VERSION ""

NS_ :

BS_:

BU_: CGW ADU Vector_XXX

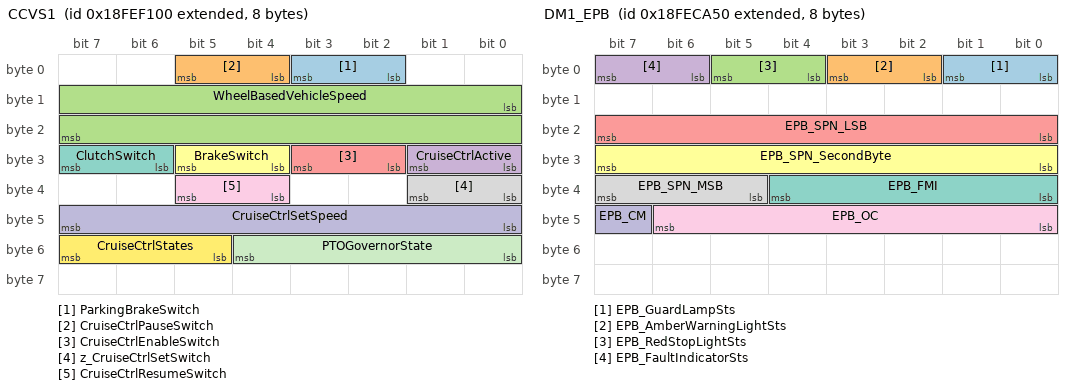
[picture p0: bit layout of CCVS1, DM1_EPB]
BO_ 2566844672 CCVS1: 8 CGW
 SG_ ParkingBrakeSwitch : 2|2@1+ (1,0) [0|3] ""  ADU
 SG_ CruiseCtrlPauseSwitch : 4|2@1+ (1,0) [0|3] ""  ADU
 SG_ WheelBasedVehicleSpeed : 8|16@1+ (0.00390625,0) [0|250.996] "km/h"  ADU
 SG_ CruiseCtrlActive : 24|2@1+ (1,0) [0|3] ""  ADU
 SG_ CruiseCtrlEnableSwitch : 26|2@1+ (1,0) [0|3] ""  ADU
 SG_ BrakeSwitch : 28|2@1+ (1,0) [0|3] ""  ADU
 SG_ ClutchSwitch : 30|2@1+ (1,0) [0|3] ""  ADU
 SG_ z_CruiseCtrlSetSwitch : 32|2@1+ (1,0) [0|3] ""  ADU
 SG_ CruiseCtrlResumeSwitch : 36|2@1+ (1,0) [0|3] ""  ADU
 SG_ CruiseCtrlSetSpeed : 40|8@1+ (1,0) [0|250] "km/h"  ADU
 SG_ PTOGovernorState : 48|5@1+ (1,0) [0|31] ""  ADU
 SG_ CruiseCtrlStates : 53|3@1+ (1,0) [0|7] ""  ADU

BO_ 2565866755 ETC2: 8 CGW
 SG_ SelectedGear : 0|8@1+ (1,-125) [-125|125] ""  ADU
 SG_ ActualGearRatio : 8|16@1+ (0.001,0) [0|64255] ""  ADU
 SG_ CurrentGear : 24|8@1+ (1,-125) [-125|125] ""  ADU

BO_ 2566834768 DM1_EPB: 8 CGW
 SG_ EPB_GuardLampSts : 0|2@1+ (1,0) [0|3] ""  ADU
 SG_ EPB_AmberWarningLightSts : 2|2@1+ (1,0) [0|3] ""  ADU
 SG_ EPB_RedStopLightSts : 4|2@1+ (1,0) [0|3] ""  ADU
 SG_ EPB_FaultIndicatorSts : 6|2@1+ (1,0) [0|3] ""  ADU
 SG_ EPB_SPN_LSB : 16|8@1+ (1,0) [0|255] ""  ADU
 SG_ EPB_SPN_SecondByte : 24|8@1+ (1,0) [0|255] ""  ADU
 SG_ EPB_FMI : 32|5@1+ (1,0) [0|31] ""  ADU
 SG_ EPB_SPN_MSB : 37|3@1+ (1,0) [0|7] ""  ADU
 SG_ EPB_OC : 40|7@1+ (1,0) [0|126] ""  ADU
 SG_ EPB_CM : 47|1@1+ (1,0) [0|1] ""  ADU

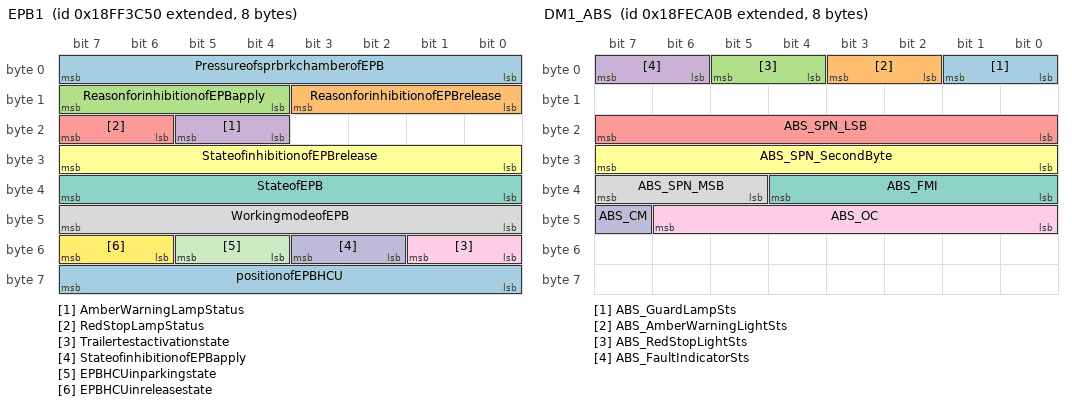
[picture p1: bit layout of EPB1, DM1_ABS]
BO_ 2566863952 EPB1: 8 CGW
 SG_ PressureofsprbrkchamberofEPB : 0|8@1+ (8,0) [0|2000] "kPa"  ADU
 SG_ ReasonforinhibitionofEPBrelease : 8|4@1+ (1,0) [0|15] ""  ADU
 SG_ ReasonforinhibitionofEPBapply : 12|4@1+ (1,0) [0|15] ""  ADU
 SG_ AmberWarningLampStatus : 20|2@1+ (1,0) [0|3] ""  ADU
 SG_ RedStopLampStatus : 22|2@1+ (1,0) [0|3] ""  ADU
 SG_ StateofinhibitionofEPBrelease : 24|8@1+ (1,0) [0|255] ""  ADU
 SG_ StateofEPB : 32|8@1+ (1,0) [0|255] ""  ADU
 SG_ WorkingmodeofEPB : 40|8@1+ (1,0) [0|255] ""  ADU
 SG_ Trailertestactivationstate : 48|2@1+ (1,0) [0|3] ""  ADU
 SG_ StateofinhibitionofEPBapply : 50|2@1+ (1,0) [0|3] ""  ADU
 SG_ EPBHCUinparkingstate : 52|2@1+ (1,0) [0|3] ""  ADU
 SG_ EPBHCUinreleasestate : 54|2@1+ (1,0) [0|3] ""  ADU
 SG_ positionofEPBHCU : 56|8@1+ (1,-125) [-125|125] "%"  ADU

BO_ 2566834699 DM1_ABS: 8 CGW
 SG_ ABS_GuardLampSts : 0|2@1+ (1,0) [0|3] ""  ADU
 SG_ ABS_AmberWarningLightSts : 2|2@1+ (1,0) [0|3] ""  ADU
 SG_ ABS_RedStopLightSts : 4|2@1+ (1,0) [0|3] ""  ADU
 SG_ ABS_FaultIndicatorSts : 6|2@1+ (1,0) [0|3] ""  ADU
 SG_ ABS_SPN_LSB : 16|8@1+ (1,0) [0|255] ""  ADU
 SG_ ABS_SPN_SecondByte : 24|8@1+ (1,0) [0|255] ""  ADU
 SG_ ABS_FMI : 32|5@1+ (1,0) [0|31] ""  ADU
 SG_ ABS_SPN_MSB : 37|3@1+ (1,0) [0|7] ""  ADU
 SG_ ABS_OC : 40|7@1+ (1,0) [0|126] ""  ADU
 SG_ ABS_CM : 47|1@1+ (1,0) [0|1] ""  ADU

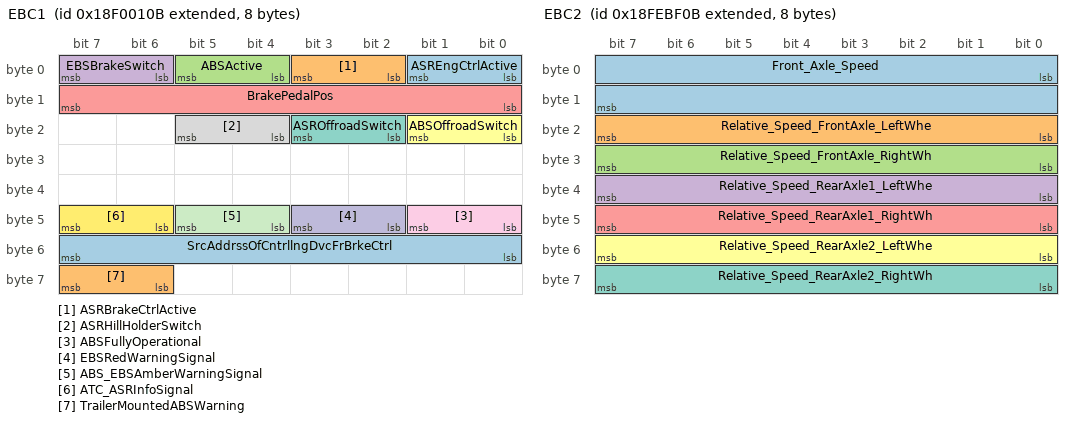
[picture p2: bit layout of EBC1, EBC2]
BO_ 2565865739 EBC1: 8 CGW
 SG_ ASREngCtrlActive : 0|2@1+ (1,0) [0|3] ""  ADU
 SG_ ASRBrakeCtrlActive : 2|2@1+ (1,0) [0|3] ""  ADU
 SG_ ABSActive : 4|2@1+ (1,0) [0|3] ""  ADU
 SG_ EBSBrakeSwitch : 6|2@1+ (1,0) [0|3] ""  ADU
 SG_ BrakePedalPos : 8|8@1+ (0.4,0) [0|100] "%"  ADU
 SG_ ABSOffroadSwitch : 16|2@1+ (1,0) [0|3] ""  ADU
 SG_ ASROffroadSwitch : 18|2@1+ (1,0) [0|3] ""  ADU
 SG_ ASRHillHolderSwitch : 20|2@1+ (1,0) [0|3] ""  ADU
 SG_ ABSFullyOperational : 40|2@1+ (1,0) [0|3] ""  ADU
 SG_ EBSRedWarningSignal : 42|2@1+ (1,0) [0|3] ""  ADU
 SG_ ABS_EBSAmberWarningSignal : 44|2@1+ (1,0) [0|3] ""  ADU
 SG_ ATC_ASRInfoSignal : 46|2@1+ (1,0) [0|3] ""  ADU
 SG_ SrcAddrssOfCntrllngDvcFrBrkeCtrl : 48|8@1+ (1,0) [0|253] ""  ADU
 SG_ TrailerMountedABSWarning : 62|2@1+ (1,0) [0|3] ""  ADU

BO_ 2566831883 EBC2: 8 CGW
 SG_ Front_Axle_Speed : 0|16@1+ (0.00390625,0) [0|250.996] "km/h"  ADU
 SG_ Relative_Speed_FrontAxle_LeftWhe : 16|8@1+ (0.0625,-7.8125) [-7.8125|7.8125] "km/h"  ADU
 SG_ Relative_Speed_FrontAxle_RightWh : 24|8@1+ (0.0625,-7.8125) [-7.8125|7.8125] "km/h"  ADU
 SG_ Relative_Speed_RearAxle1_LeftWhe : 32|8@1+ (0.0625,-7.8125) [-7.8125|7.8125] "km/h"  ADU
 SG_ Relative_Speed_RearAxle1_RightWh : 40|8@1+ (0.0625,-7.8125) [-7.8125|7.8125] "km/h"  ADU
 SG_ Relative_Speed_RearAxle2_LeftWhe : 48|8@1+ (0.0625,-7.8125) [-7.8125|7.8125] "km/h"  ADU
 SG_ Relative_Speed_RearAxle2_RightWh : 56|8@1+ (0.0625,-7.8125) [-7.8125|7.8125] "km/h"  ADU

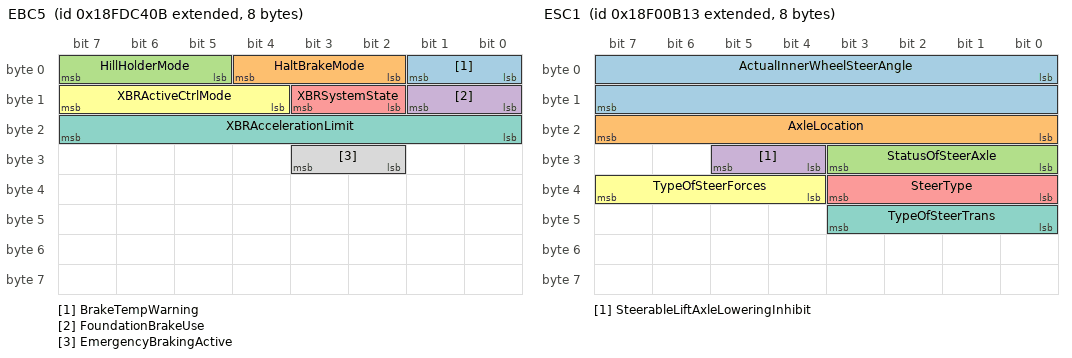
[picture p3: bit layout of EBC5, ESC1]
BO_ 2566767627 EBC5: 8 CGW
 SG_ BrakeTempWarning : 0|2@1+ (1,0) [0|3] ""  ADU
 SG_ HaltBrakeMode : 2|3@1+ (1,0) [0|7] ""  ADU
 SG_ HillHolderMode : 5|3@1+ (1,0) [0|7] ""  ADU
 SG_ FoundationBrakeUse : 8|2@1+ (1,0) [0|3] ""  ADU
 SG_ XBRSystemState : 10|2@1+ (1,0) [0|3] ""  ADU
 SG_ XBRActiveCtrlMode : 12|4@1+ (1,0) [0|15] ""  ADU
 SG_ XBRAccelerationLimit : 16|8@1+ (0.1,-12.5) [-12.5|12.5] "m/s2"  ADU
 SG_ EmergencyBrakingActive : 26|2@1+ (1,0) [0|3] ""  ADU

BO_ 2565868307 ESC1: 8 CGW
 SG_ ActualInnerWheelSteerAngle : 0|16@1+ (0.00390625,-125) [-125|125] "deg"  ADU
 SG_ AxleLocation : 16|8@1+ (1,0) [0|255] ""  ADU
 SG_ StatusOfSteerAxle : 24|4@1+ (1,0) [0|15] ""  ADU
 SG_ SteerableLiftAxleLoweringInhibit : 28|2@1+ (1,0) [0|3] ""  ADU
 SG_ SteerType : 32|4@1+ (1,0) [0|15] ""  ADU
 SG_ TypeOfSteerForces : 36|4@1+ (1,0) [0|15] ""  ADU
 SG_ TypeOfSteerTrans : 40|4@1+ (1,0) [0|15] ""  ADU

BO_ 2566811659 CVW: 8 CGW
 SG_ PoweredVehicleWeight : 0|16@1+ (10,0) [0|642550] "kg"  ADU
 SG_ GrossCombinationVehicleWeight : 16|16@1+ (10,0) [0|642550] "kg"  ADU

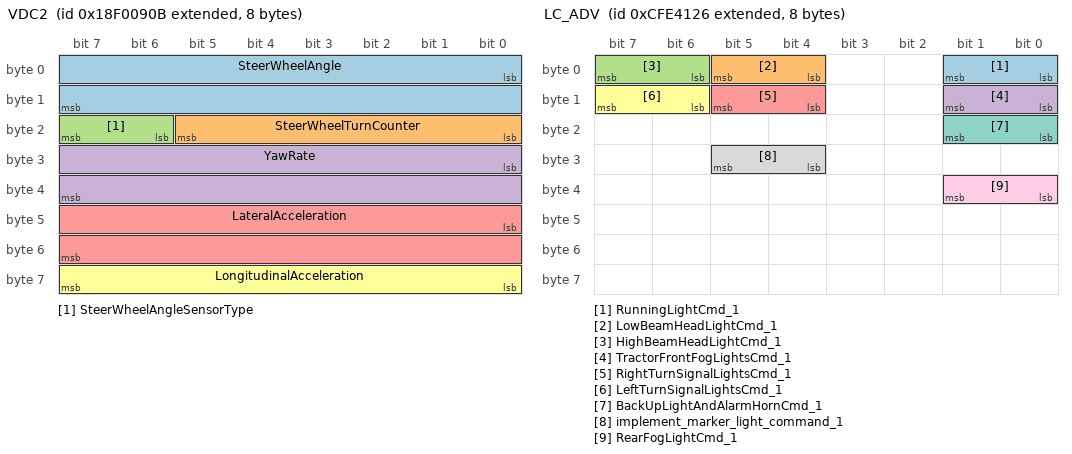
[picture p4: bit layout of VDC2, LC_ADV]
BO_ 2565867787 VDC2: 8 CGW
 SG_ SteerWheelAngle : 0|16@1+ (0.0009765625,-31.375) [-31.375|31.374] "rad"  ADU
 SG_ SteerWheelTurnCounter : 16|6@1+ (1,-32) [-32|31] "turns"  ADU
 SG_ SteerWheelAngleSensorType : 22|2@1+ (1,0) [0|3] ""  ADU
 SG_ YawRate : 24|16@1+ (0.0001220703125,-3.92) [-3.92|3.92] "rad/s"  ADU
 SG_ LateralAcceleration : 40|16@1+ (0.00048828125,-15.687) [-15.687|15.687] "m/s2"  ADU
 SG_ LongitudinalAcceleration : 56|8@1+ (0.1,-12.5) [-12.5|12.5] "m/s2"  ADU

BO_ 2365473062 LC_ADV: 8 ADU
 SG_ RunningLightCmd_1 : 0|2@1+ (1,0) [0|3] ""  CGW
 SG_ LowBeamHeadLightCmd_1 : 4|2@1+ (1,0) [0|3] ""  CGW
 SG_ HighBeamHeadLightCmd_1 : 6|2@1+ (1,0) [0|3] ""  CGW
 SG_ TractorFrontFogLightsCmd_1 : 8|2@1+ (1,0) [0|3] ""  CGW
 SG_ RightTurnSignalLightsCmd_1 : 12|2@1+ (1,0) [0|3] ""  CGW
 SG_ LeftTurnSignalLightsCmd_1 : 14|2@1+ (1,0) [0|3] ""  CGW
 SG_ BackUpLightAndAlarmHornCmd_1 : 16|2@1+ (1,0) [0|3] ""  CGW
 SG_ implement_marker_light_command_1 : 28|2@1+ (1,0) [0|3] ""  CGW
 SG_ RearFogLightCmd_1 : 32|2@1+ (1,0) [0|3] ""  CGW

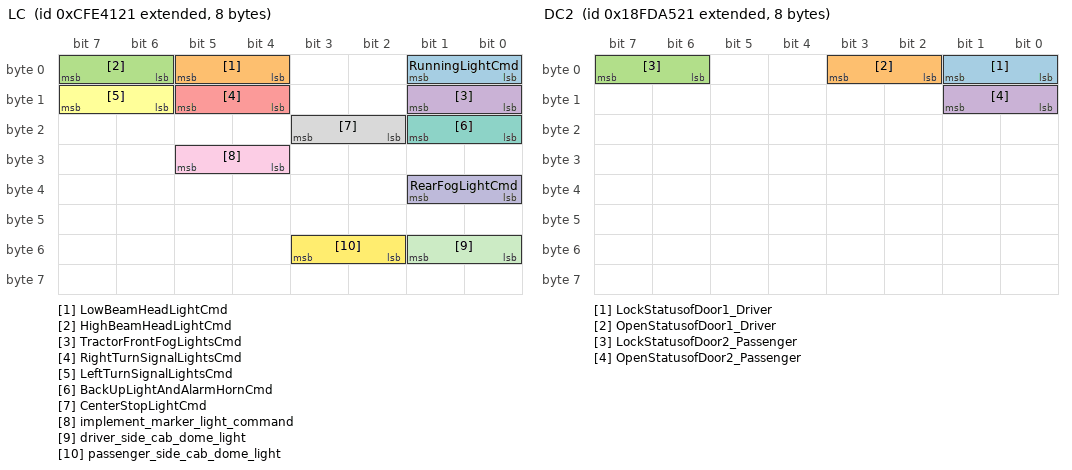
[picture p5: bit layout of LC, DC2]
BO_ 2365473057 LC: 8 CGW
 SG_ RunningLightCmd : 0|2@1+ (1,0) [0|3] ""  ADU
 SG_ LowBeamHeadLightCmd : 4|2@1+ (1,0) [0|3] ""  ADU
 SG_ HighBeamHeadLightCmd : 6|2@1+ (1,0) [0|3] ""  ADU
 SG_ TractorFrontFogLightsCmd : 8|2@1+ (1,0) [0|3] ""  ADU
 SG_ RightTurnSignalLightsCmd : 12|2@1+ (1,0) [0|3] ""  ADU
 SG_ LeftTurnSignalLightsCmd : 14|2@1+ (1,0) [0|3] ""  ADU
 SG_ BackUpLightAndAlarmHornCmd : 16|2@1+ (1,0) [0|3] ""  ADU
 SG_ CenterStopLightCmd : 18|2@1+ (1,0) [0|3] ""  ADU
 SG_ implement_marker_light_command : 28|2@1+ (1,0) [0|3] ""  ADU
 SG_ RearFogLightCmd : 32|2@1+ (1,0) [0|3] ""  ADU
 SG_ driver_side_cab_dome_light : 48|2@1+ (1,0) [0|3] ""  ADU
 SG_ passenger_side_cab_dome_light : 50|2@1+ (1,0) [0|3] ""  ADU

BO_ 2566759713 DC2: 8 CGW
 SG_ LockStatusofDoor1_Driver : 0|2@1+ (1,0) [0|3] ""  ADU
 SG_ OpenStatusofDoor1_Driver : 2|2@1+ (1,0) [0|3] ""  ADU
 SG_ LockStatusofDoor2_Passenger : 6|2@1+ (1,0) [0|3] ""  ADU
 SG_ OpenStatusofDoor2_Passenger : 8|2@1+ (1,0) [0|3] ""  ADU

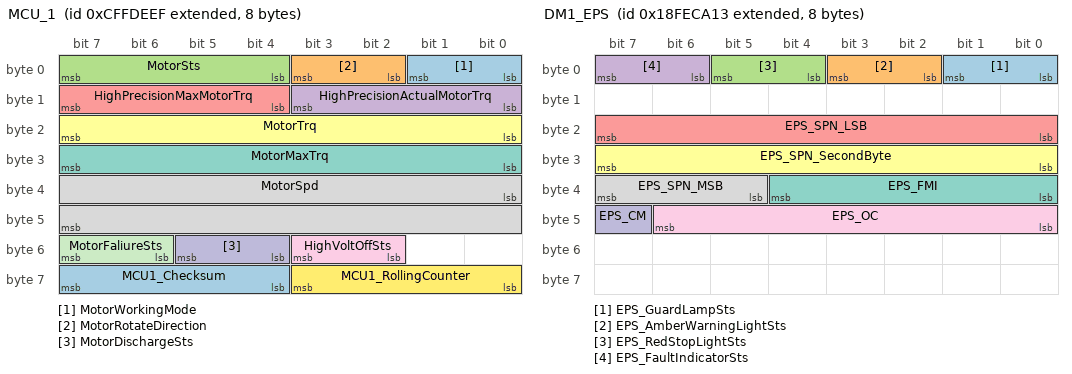
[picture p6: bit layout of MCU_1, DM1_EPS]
BO_ 2365578991 MCU_1: 8 CGW
 SG_ MotorWorkingMode : 0|2@1+ (1,0) [0|3] ""  ADU
 SG_ MotorRotateDirection : 2|2@1+ (1,0) [0|3] ""  ADU
 SG_ MotorSts : 4|4@1+ (1,0) [0|15] ""  ADU
 SG_ HighPrecisionActualMotorTrq : 8|4@1+ (1,0) [0|15] ""  ADU
 SG_ HighPrecisionMaxMotorTrq : 12|4@1+ (1,0) [0|15] ""  ADU
 SG_ MotorTrq : 16|8@1+ (1,-125) [-125|125] "%"  ADU
 SG_ MotorMaxTrq : 24|8@1+ (1,-125) [-125|125] "%"  ADU
 SG_ MotorSpd : 32|16@1+ (0.125,0) [0|8031.875] "rpm"  ADU
 SG_ HighVoltOffSts : 50|2@1+ (1,0) [0|3] ""  ADU
 SG_ MotorDischargeSts : 52|2@1+ (1,0) [0|3] ""  ADU
 SG_ MotorFaliureSts : 54|2@1+ (1,0) [0|3] ""  ADU
 SG_ MCU1_RollingCounter : 56|4@1+ (1,0) [0|15] ""  ADU
 SG_ MCU1_Checksum : 60|4@1+ (1,0) [0|15] ""  ADU

BO_ 2566834707 DM1_EPS: 8 CGW
 SG_ EPS_GuardLampSts : 0|2@1+ (1,0) [0|3] ""  ADU
 SG_ EPS_AmberWarningLightSts : 2|2@1+ (1,0) [0|3] ""  ADU
 SG_ EPS_RedStopLightSts : 4|2@1+ (1,0) [0|3] ""  ADU
 SG_ EPS_FaultIndicatorSts : 6|2@1+ (1,0) [0|3] ""  ADU
 SG_ EPS_SPN_LSB : 16|8@1+ (1,0) [0|255] ""  ADU
 SG_ EPS_SPN_SecondByte : 24|8@1+ (1,0) [0|255] ""  ADU
 SG_ EPS_FMI : 32|5@1+ (1,0) [0|31] ""  ADU
 SG_ EPS_SPN_MSB : 37|3@1+ (1,0) [0|7] ""  ADU
 SG_ EPS_OC : 40|7@1+ (1,0) [0|126] ""  ADU
 SG_ EPS_CM : 47|1@1+ (1,0) [0|1] ""  ADU

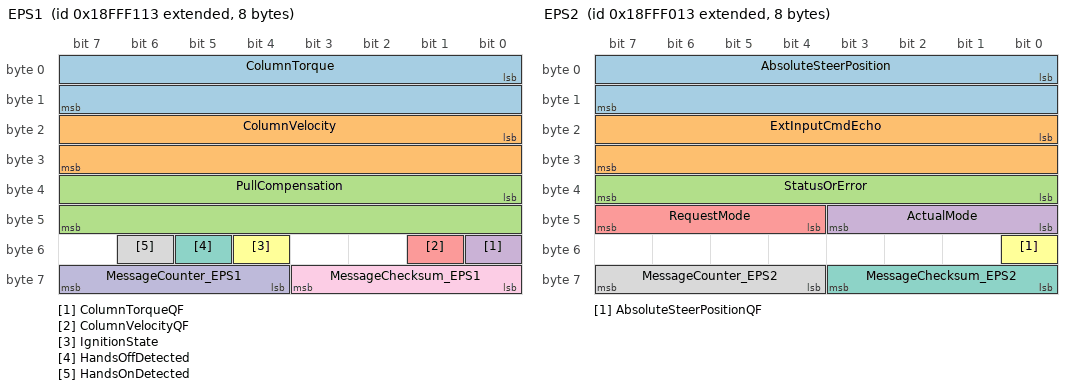
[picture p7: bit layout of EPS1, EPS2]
BO_ 2566910227 EPS1: 8 CGW
 SG_ ColumnTorque : 0|16@1- (0.0009765625,-10) [-10|10] "Nm"  ADU
 SG_ ColumnVelocity : 16|16@1- (0.0009765625,-5) [-5|5] "rev/s"  ADU
 SG_ PullCompensation : 32|16@1- (0.0625,-1024) [-1024|1024] "deg"  ADU
 SG_ ColumnTorqueQF : 48|1@1+ (1,0) [0|1] ""  ADU
 SG_ ColumnVelocityQF : 49|1@1+ (1,0) [0|1] ""  ADU
 SG_ IgnitionState : 52|1@1+ (1,0) [0|1] ""  ADU
 SG_ HandsOffDetected : 53|1@1+ (1,0) [0|1] ""  ADU
 SG_ HandsOnDetected : 54|1@1+ (1,0) [0|1] ""  ADU
 SG_ MessageChecksum_EPS1 : 56|4@1+ (1,0) [0|15] ""  ADU
 SG_ MessageCounter_EPS1 : 60|4@1+ (1,0) [0|15] ""  ADU

BO_ 2566909971 EPS2: 8 CGW
 SG_ AbsoluteSteerPosition : 0|16@1- (0.0625,-1224) [-1224|1224] "deg"  ADU
 SG_ ExtInputCmdEcho : 16|16@1- (0.0625,-1224) [-1224|1224] "deg"  ADU
 SG_ StatusOrError : 32|8@1+ (1,0) [0|0] ""  ADU
 SG_ ActualMode : 40|4@1+ (1,0) [0|15] ""  ADU
 SG_ RequestMode : 44|4@1+ (1,0) [0|15] ""  ADU
 SG_ AbsoluteSteerPositionQF : 48|1@1+ (1,0) [0|1] ""  ADU
 SG_ MessageChecksum_EPS2 : 56|4@1+ (1,0) [0|15] ""  ADU
 SG_ MessageCounter_EPS2 : 60|4@1+ (1,0) [0|15] ""  ADU

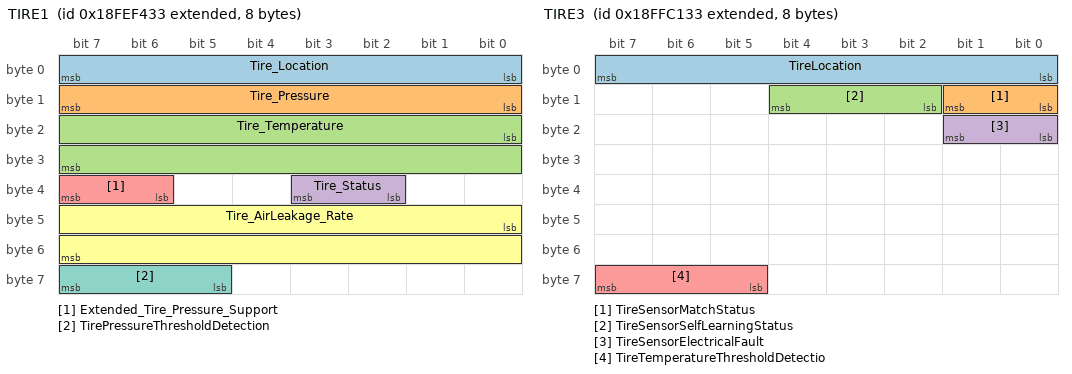
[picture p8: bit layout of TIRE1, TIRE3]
BO_ 2566845491 TIRE1: 8 CGW
 SG_ Tire_Location : 0|8@1+ (1,0) [0|255] ""  ADU
 SG_ Tire_Pressure : 8|8@1+ (4,0) [0|250] "kpa"  ADU
 SG_ Tire_Temperature : 16|16@1+ (0.03125,-273) [-273|1734.96875] "℃"  ADU
 SG_ Tire_Status : 34|2@1+ (1,0) [0|3] ""  ADU
 SG_ Extended_Tire_Pressure_Support : 38|2@1+ (1,0) [0|3] ""  ADU
 SG_ Tire_AirLeakage_Rate : 40|16@1+ (0.1,0) [0|6425.5] "Pa/s"  ADU
 SG_ TirePressureThresholdDetection : 61|3@1+ (1,0) [0|7] ""  ADU

BO_ 2566668851 TIRE2: 8 CGW
 SG_ Tire_Location : 0|8@1+ (1,0) [0|255] ""  ADU
 SG_ Tire_PressExtedRage : 8|16@1+ (1,0) [0|64255] "kpa"  ADU
 SG_ RequiredTirePressure : 24|16@1+ (1,0) [0|64255] "kpa"  ADU

BO_ 2566897971 TIRE3: 8 CGW
 SG_ TireLocation : 0|8@1+ (1,0) [0|255] ""  ADU
 SG_ TireSensorMatchStatus : 8|2@1+ (1,0) [0|3] ""  ADU
 SG_ TireSensorSelfLearningStatus : 10|3@1+ (1,0) [0|7] ""  ADU
 SG_ TireSensorElectricalFault : 16|2@1+ (1,0) [0|3] ""  ADU
 SG_ TireTemperatureThresholdDetectio : 61|3@1+ (1,0) [0|7] ""  ADU

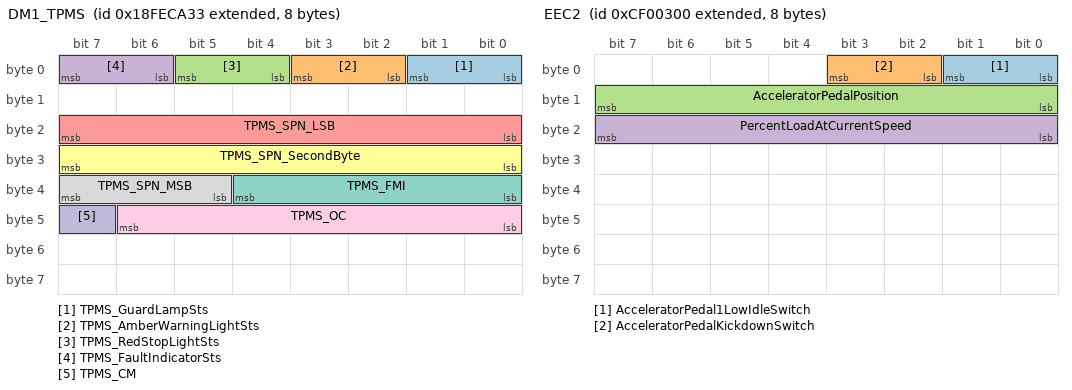
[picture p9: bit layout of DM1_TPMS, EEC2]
BO_ 2566834739 DM1_TPMS: 8 CGW
 SG_ TPMS_GuardLampSts : 0|2@1+ (1,0) [0|3] ""  ADU
 SG_ TPMS_AmberWarningLightSts : 2|2@1+ (1,0) [0|3] ""  ADU
 SG_ TPMS_RedStopLightSts : 4|2@1+ (1,0) [0|3] ""  ADU
 SG_ TPMS_FaultIndicatorSts : 6|2@1+ (1,0) [0|3] ""  ADU
 SG_ TPMS_SPN_LSB : 16|8@1+ (1,0) [0|255] ""  ADU
 SG_ TPMS_SPN_SecondByte : 24|8@1+ (1,0) [0|255] ""  ADU
 SG_ TPMS_FMI : 32|5@1+ (1,0) [0|31] ""  ADU
 SG_ TPMS_SPN_MSB : 37|3@1+ (1,0) [0|7] ""  ADU
 SG_ TPMS_OC : 40|7@1+ (1,0) [0|126] ""  ADU
 SG_ TPMS_CM : 47|1@1+ (1,0) [0|1] ""  ADU

BO_ 2364539648 EEC2: 8 CGW
 SG_ AcceleratorPedal1LowIdleSwitch : 0|2@1+ (1,0) [0|3] ""  ADU
 SG_ AcceleratorPedalKickdownSwitch : 2|2@1+ (1,0) [0|3] ""  ADU
 SG_ AcceleratorPedalPosition : 8|8@1+ (0.4,0) [0|100] "%"  ADU
 SG_ PercentLoadAtCurrentSpeed : 16|8@1+ (1,0) [0|250] "%"  ADU

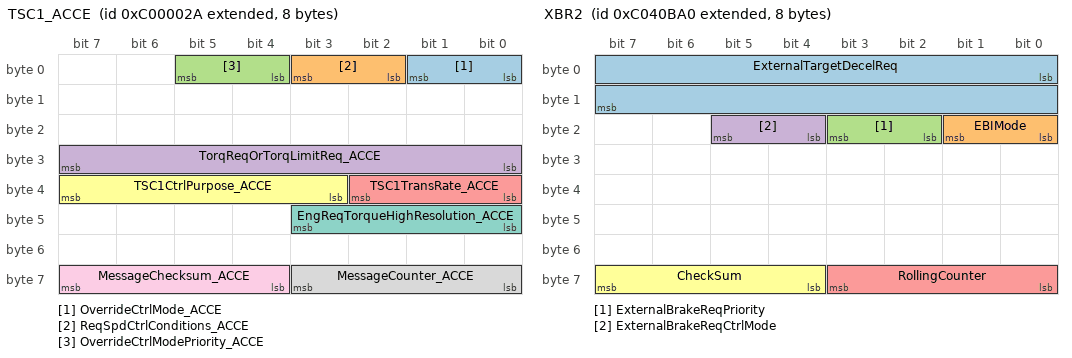
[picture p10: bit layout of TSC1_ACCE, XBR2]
BO_ 2348810282 TSC1_ACCE: 8 ADU
 SG_ OverrideCtrlMode_ACCE : 0|2@1+ (1,0) [0|3] ""  CGW
 SG_ ReqSpdCtrlConditions_ACCE : 2|2@1+ (1,0) [0|3] ""  CGW
 SG_ OverrideCtrlModePriority_ACCE : 4|2@1+ (1,0) [0|3] ""  CGW
 SG_ TorqReqOrTorqLimitReq_ACCE : 24|8@1+ (1,-125) [-125|125] "%"  CGW
 SG_ TSC1TransRate_ACCE : 32|3@1+ (1,0) [0|7] ""  CGW
 SG_ TSC1CtrlPurpose_ACCE : 35|5@1+ (1,0) [0|31] ""  CGW
 SG_ EngReqTorqueHighResolution_ACCE : 40|4@1+ (0.125,0) [0|0.875] "%"  CGW
 SG_ MessageCounter_ACCE : 56|4@1+ (1,0) [0|15] ""  CGW
 SG_ MessageChecksum_ACCE : 60|4@1+ (1,0) [0|15] ""  CGW

BO_ 2349075360 XBR2: 8 ADU
 SG_ ExternalTargetDecelReq : 0|16@1+ (0.0004882813,-15.687) [-15.687|15.687] "m/s2"  CGW
 SG_ EBIMode : 16|2@1+ (1,0) [0|3] ""  CGW
 SG_ ExternalBrakeReqPriority : 18|2@1+ (1,0) [0|3] ""  CGW
 SG_ ExternalBrakeReqCtrlMode : 20|2@1+ (1,0) [0|3] ""  CGW
 SG_ RollingCounter : 56|4@1+ (1,0) [0|15] ""  CGW
 SG_ CheckSum : 60|4@1+ (1,0) [0|15] ""  CGW

BO_ 2348875814 TC1_ADU: 8 ADU
 SG_ TransmissionGearReq : 16|8@1+ (1,-125) [-125|125] ""  CGW

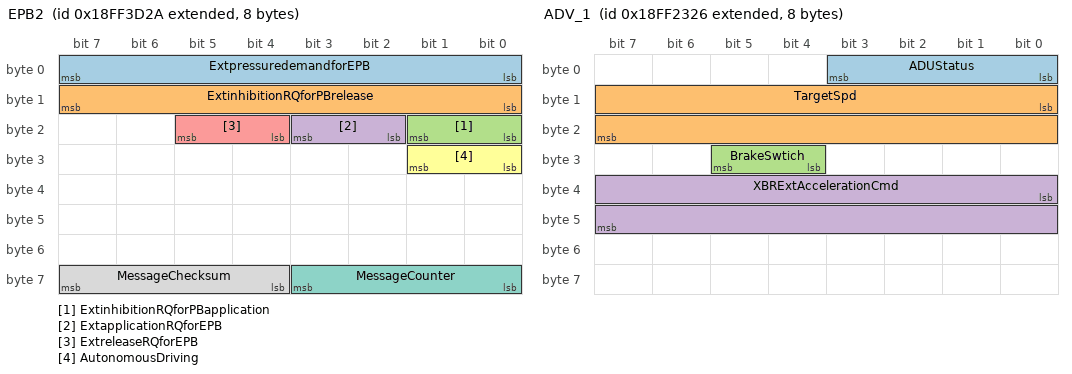
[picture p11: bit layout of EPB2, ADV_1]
BO_ 2566864170 EPB2: 8 ADU
 SG_ ExtpressuredemandforEPB : 0|8@1+ (0.4,0) [0|100] "%"  CGW
 SG_ ExtinhibitionRQforPBrelease : 8|8@1+ (1,0) [0|255] ""  CGW
 SG_ ExtinhibitionRQforPBapplication : 16|2@1+ (1,0) [0|3] ""  CGW
 SG_ ExtapplicationRQforEPB : 18|2@1+ (1,0) [0|3] ""  CGW
 SG_ ExtreleaseRQforEPB : 20|2@1+ (1,0) [0|3] ""  CGW
 SG_ AutonomousDriving : 24|2@1+ (1,0) [0|3] ""  CGW
 SG_ MessageCounter : 56|4@1+ (1,0) [0|15] ""  CGW
 SG_ MessageChecksum : 60|4@1+ (1,0) [0|15] ""  CGW

BO_ 2566857510 ADV_1: 8 ADU
 SG_ ADUStatus : 0|4@1+ (1,0) [0|15] ""  CGW
 SG_ TargetSpd : 8|16@1+ (0.00390625,0) [0|250.996] "km/h"  CGW
 SG_ BrakeSwtich : 28|2@1+ (1,0) [0|3] ""  CGW
 SG_ XBRExtAccelerationCmd : 32|16@1+ (0.00048828,-15.687) [-15.687|15.687] "m/s2"  CGW

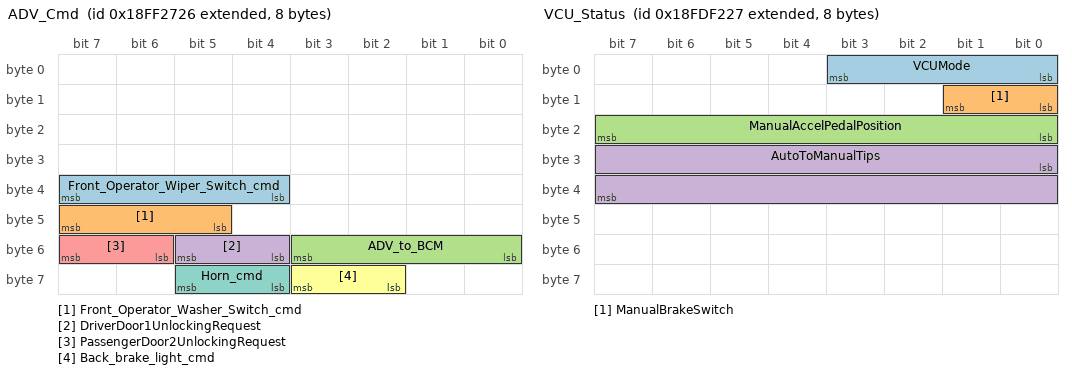
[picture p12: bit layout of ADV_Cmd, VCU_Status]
BO_ 2566858534 ADV_Cmd: 8 ADU
 SG_ Front_Operator_Wiper_Switch_cmd : 36|4@1+ (1,0) [0|8] ""  CGW
 SG_ Front_Operator_Washer_Switch_cmd : 45|3@1+ (1,0) [0|7] ""  CGW
 SG_ ADV_to_BCM : 48|4@1+ (1,0) [0|15] ""  CGW
 SG_ DriverDoor1UnlockingRequest : 52|2@1+ (1,0) [0|3] ""  Vector_XXX
 SG_ PassengerDoor2UnlockingRequest : 54|2@1+ (1,0) [0|3] ""  Vector_XXX
 SG_ Back_brake_light_cmd : 58|2@1+ (1,0) [0|3] ""  CGW
 SG_ Horn_cmd : 60|2@1+ (1,0) [0|3] ""  CGW

BO_ 2566779431 VCU_Status: 8 CGW
 SG_ VCUMode : 0|4@1+ (1,0) [0|15] ""  ADU
 SG_ ManualBrakeSwitch : 8|2@1+ (1,0) [0|3] ""  ADU
 SG_ ManualAccelPedalPosition : 16|8@1+ (0.4,0) [0|100] "%"  ADU
 SG_ AutoToManualTips : 24|16@1+ (1,0) [0|65535] ""  ADU

BO_ 2566769953 OWW: 8 CGW
 SG_ FrontOperatorWiperSwitch : 4|4@1+ (1,0) [0|15] ""  ADU
 SG_ FrontOperatorWasherSwitch : 45|3@1+ (1,0) [0|7] ""  ADU

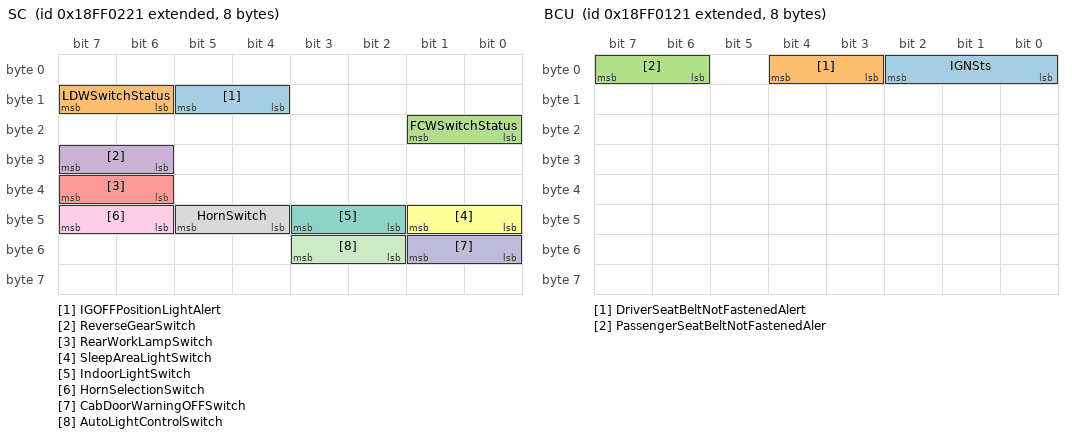
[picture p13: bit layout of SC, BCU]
BO_ 2566849057 SC: 8 CGW
 SG_ IGOFFPositionLightAlert : 12|2@1+ (1,0) [0|3] ""  ADU
 SG_ LDWSwitchStatus : 14|2@1+ (1,0) [0|3] ""  ADU
 SG_ FCWSwitchStatus : 16|2@1+ (1,0) [0|3] ""  ADU
 SG_ ReverseGearSwitch : 30|2@1+ (1,0) [0|3] ""  ADU
 SG_ RearWorkLampSwitch : 38|2@1+ (1,0) [0|3] ""  ADU
 SG_ SleepAreaLightSwitch : 40|2@1+ (1,0) [0|3] ""  ADU
 SG_ IndoorLightSwitch : 42|2@1+ (1,0) [0|3] ""  ADU
 SG_ HornSwitch : 44|2@1+ (1,0) [0|3] ""  ADU
 SG_ HornSelectionSwitch : 46|2@1+ (1,0) [0|3] ""  ADU
 SG_ CabDoorWarningOFFSwitch : 48|2@1+ (1,0) [0|3] ""  ADU
 SG_ AutoLightControlSwitch : 50|2@1+ (1,0) [0|3] ""  ADU

BO_ 2566848801 BCU: 8 CGW
 SG_ IGNSts : 0|3@1+ (1,0) [0|7] ""  ADU
 SG_ DriverSeatBeltNotFastenedAlert : 3|2@1+ (1,0) [0|3] ""  ADU
 SG_ PassengerSeatBeltNotFastenedAler : 6|2@1+ (1,0) [0|3] ""  ADU

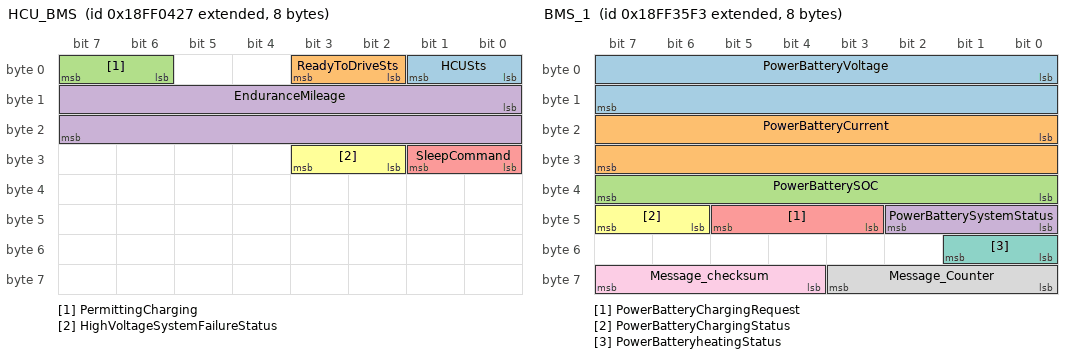
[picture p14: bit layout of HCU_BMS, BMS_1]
BO_ 2566849575 HCU_BMS: 8 CGW
 SG_ HCUSts : 0|2@1+ (1,0) [0|3] ""  ADU
 SG_ ReadyToDriveSts : 2|2@1+ (1,0) [0|3] ""  ADU
 SG_ PermittingCharging : 6|2@1+ (1,0) [0|3] ""  ADU
 SG_ EnduranceMileage : 8|16@1+ (0.125,0) [0|8031.875] "km"  ADU
 SG_ SleepCommand : 24|2@1+ (1,0) [0|3] ""  ADU
 SG_ HighVoltageSystemFailureStatus : 26|2@1+ (1,0) [0|3] ""  ADU

BO_ 2566862323 BMS_1: 8 CGW
 SG_ PowerBatteryVoltage : 0|16@1+ (0.05,0) [0|3212.75] "V"  ADU
 SG_ PowerBatteryCurrent : 16|16@1+ (0.05,-1600) [-1600|1612.75] "A"  ADU
 SG_ PowerBatterySOC : 32|8@1+ (1,0) [0|100] ""  ADU
 SG_ PowerBatterySystemStatus : 40|3@1+ (1,0) [0|7] ""  ADU
 SG_ PowerBatteryChargingRequest : 43|3@1+ (1,0) [0|7] ""  ADU
 SG_ PowerBatteryChargingStatus : 46|2@1+ (1,0) [0|3] ""  ADU
 SG_ PowerBatteryheatingStatus : 48|2@1+ (1,0) [0|3] ""  ADU
 SG_ Message_Counter : 56|4@1+ (1,0) [0|15] ""  ADU
 SG_ Message_checksum : 60|4@1+ (1,0) [0|15] ""  ADU

BO_ 2566863603 BMS_5: 8 CGW
 SG_ BMSMainnegativeCoilDriveState : 14|2@1+ (1,0) [0|3] ""  ADU
 SG_ PowerBatterySOH : 16|8@1+ (0.4,0) [0|100] "%"  ADU
 SG_ MainNegativeRelayDisconnectReque : 38|2@1+ (1,0) [0|3] ""  ADU
 SG_ MainNegativeRelayStatus : 40|3@1+ (1,0) [0|7] ""  ADU
 SG_ PositiveRelayControlCommand : 43|2@1+ (1,0) [0|3] ""  ADU
 SG_ NegativeRelayControlCommand : 46|2@1+ (1,0) [0|3] ""  ADU
 SG_ ChargingPlugConnectionStatus : 48|2@1+ (1,0) [0|3] ""  ADU
 SG_ ChargingPlugConnectionStatus2 : 50|2@0+ (1,0) [0|3] ""  Vector_XXX
 SG_ PositiveRelayStatus : 56|3@1+ (1,0) [0|7] ""  ADU
 SG_ NegativeRelayStatus : 59|3@1+ (1,0) [0|7] ""  ADU

BO_ 2566840343 VD: 8 CGW
 SG_ TripDistance : 0|32@1+ (0.125,0) [0|526385151.9] "km"  ADU
 SG_ TotalVehicleDistance : 32|32@1+ (0.125,0) [0|526385151.9] "km"  ADU

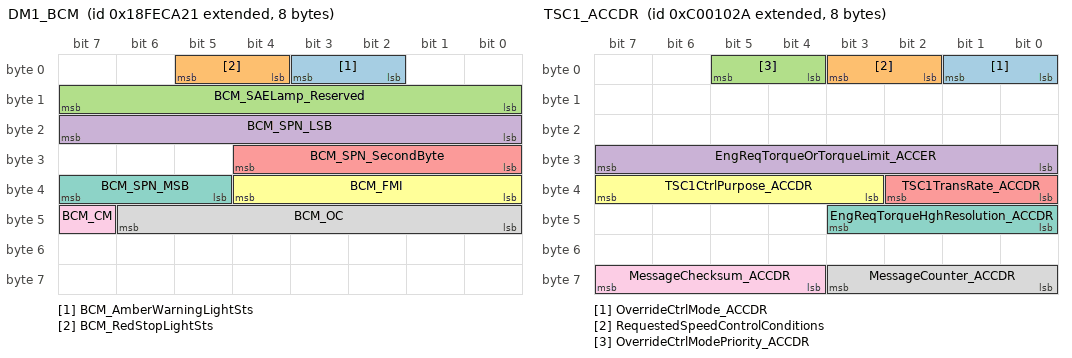
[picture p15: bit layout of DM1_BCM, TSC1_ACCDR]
BO_ 2566834721 DM1_BCM: 8 CGW
 SG_ BCM_AmberWarningLightSts : 2|2@1+ (1,0) [0|3] ""  ADU
 SG_ BCM_RedStopLightSts : 4|2@1+ (1,0) [0|3] ""  ADU
 SG_ BCM_SAELamp_Reserved : 8|8@1+ (1,0) [0|255] ""  ADU
 SG_ BCM_SPN_LSB : 16|8@1+ (1,0) [0|255] ""  ADU
 SG_ BCM_SPN_SecondByte : 24|5@1+ (1,0) [0|31] ""  ADU
 SG_ BCM_FMI : 32|5@1+ (1,0) [0|31] ""  ADU
 SG_ BCM_SPN_MSB : 37|3@1+ (1,0) [0|7] ""  ADU
 SG_ BCM_OC : 40|7@1+ (1,0) [0|126] ""  ADU
 SG_ BCM_CM : 47|1@1+ (1,0) [0|1] ""  ADU

BO_ 2348814378 TSC1_ACCDR: 8 ADU
 SG_ OverrideCtrlMode_ACCDR : 0|2@1+ (1,0) [0|3] ""  CGW
 SG_ RequestedSpeedControlConditions : 2|2@1+ (1,0) [0|3] ""  CGW
 SG_ OverrideCtrlModePriority_ACCDR : 4|2@1+ (1,0) [0|3] ""  CGW
 SG_ EngReqTorqueOrTorqueLimit_ACCER : 24|8@1+ (1,-125) [-125|125] "%"  CGW
 SG_ TSC1TransRate_ACCDR : 32|3@1+ (1,0) [0|7] ""  CGW
 SG_ TSC1CtrlPurpose_ACCDR : 35|5@1+ (1,0) [0|31] ""  CGW
 SG_ EngReqTorqueHghResolution_ACCDR : 40|4@1+ (0.125,0) [0|0.875] ""  CGW
 SG_ MessageCounter_ACCDR : 56|4@1+ (1,0) [0|15] ""  CGW
 SG_ MessageChecksum_ACCDR : 60|4@1+ (1,0) [0|15] ""  CGW

BO_ 2566841127 EC_EM1: 40 CGW
 SG_ EngineSpeedAtIdle_Point1 : 0|16@1+ (0.125,0) [0|8031.875] "km"  ADU
 SG_ Reference_engine_torque_Drive : 152|16@1+ (1,0) [0|64255] "Nm"  ADU
 SG_ SupportVariableRateTSC1 : 272|8@1+ (1,0) [0|255] ""  ADU

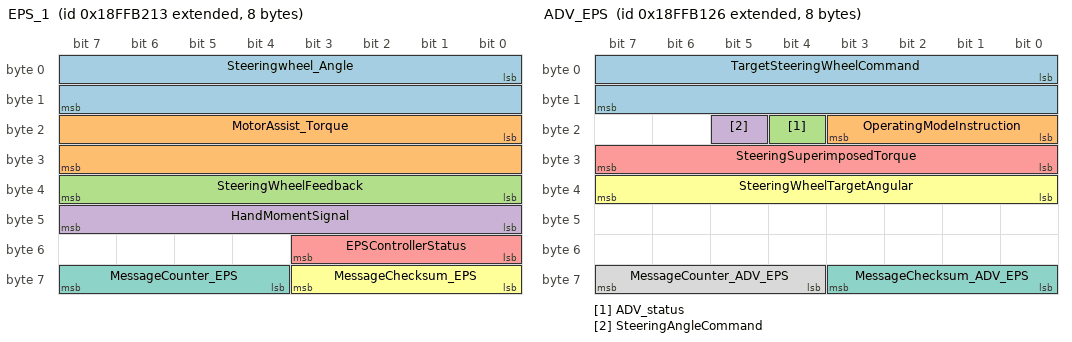
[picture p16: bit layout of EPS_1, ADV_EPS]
BO_ 2566894099 EPS_1: 8 CGW
 SG_ Steeringwheel_Angle : 0|16@1+ (0.1,-1575) [-1575|1575] "°"  ADU
 SG_ MotorAssist_Torque : 16|16@1+ (0.000152,-5) [-5|5] "Nm"  ADU
 SG_ SteeringWheelFeedback : 32|8@1- (10,0) [50|540] "°/s"  ADU
 SG_ HandMomentSignal : 40|8@1+ (0.1,-12.8) [-12.8|12.7] "Nm"  ADU
 SG_ EPSControllerStatus : 48|4@1+ (1,0) [0|15] ""  ADU
 SG_ MessageChecksum_EPS : 56|4@1+ (1,0) [0|15] ""  ADU
 SG_ MessageCounter_EPS : 60|4@1+ (1,0) [0|15] ""  ADU

BO_ 2566893862 ADV_EPS: 8 ADU
 SG_ TargetSteeringWheelCommand : 0|16@1+ (0.1,-1575) [-1575|1575] "°"  ADU
 SG_ OperatingModeInstruction : 16|4@1+ (1,0) [0|15] ""  ADU
 SG_ ADV_status : 20|1@1+ (1,0) [0|1] ""  ADU
 SG_ SteeringAngleCommand : 21|1@1+ (1,0) [0|1] ""  ADU
 SG_ SteeringSuperimposedTorque : 24|8@1+ (1,-12.8) [-12.8|12.7] "Nm"  Vector_XXX
 SG_ SteeringWheelTargetAngular : 32|8@1+ (2,50) [50|540] "°/s"  ADU
 SG_ MessageChecksum_ADV_EPS : 56|4@1+ (1,0) [0|15] ""  ADU
 SG_ MessageCounter_ADV_EPS : 60|4@1+ (1,0) [0|15] ""  ADU

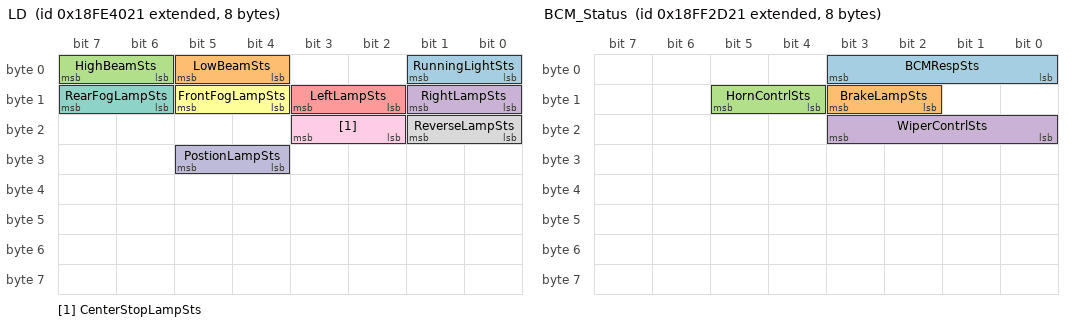
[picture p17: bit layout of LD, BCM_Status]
BO_ 2566799393 LD: 8 CGW
 SG_ RunningLightSts : 0|2@1+ (1,0) [0|3] ""  ADU
 SG_ LowBeamSts : 4|2@1+ (1,0) [0|3] ""  ADU
 SG_ HighBeamSts : 6|2@1+ (1,0) [0|3] ""  ADU
 SG_ RightLampSts : 8|2@1+ (1,0) [0|3] ""  ADU
 SG_ LeftLampSts : 10|2@1+ (1,0) [0|3] ""  ADU
 SG_ FrontFogLampSts : 12|2@1+ (1,0) [0|3] ""  ADU
 SG_ RearFogLampSts : 14|2@1+ (1,0) [0|3] ""  ADU
 SG_ ReverseLampSts : 16|2@1+ (1,0) [0|3] ""  ADU
 SG_ CenterStopLampSts : 18|2@1+ (1,0) [0|3] ""  ADU
 SG_ PostionLampSts : 28|2@1+ (1,0) [0|3] ""  ADU

BO_ 2566860065 BCM_Status: 8 CGW
 SG_ BCMRespSts : 0|4@1+ (1,0) [0|15] ""  ADU
 SG_ BrakeLampSts : 10|2@1+ (1,0) [0|3] ""  ADU
 SG_ HornContrlSts : 12|2@1+ (1,0) [0|3] ""  ADU
 SG_ WiperContrlSts : 16|4@1+ (1,0) [0|3] ""  ADU

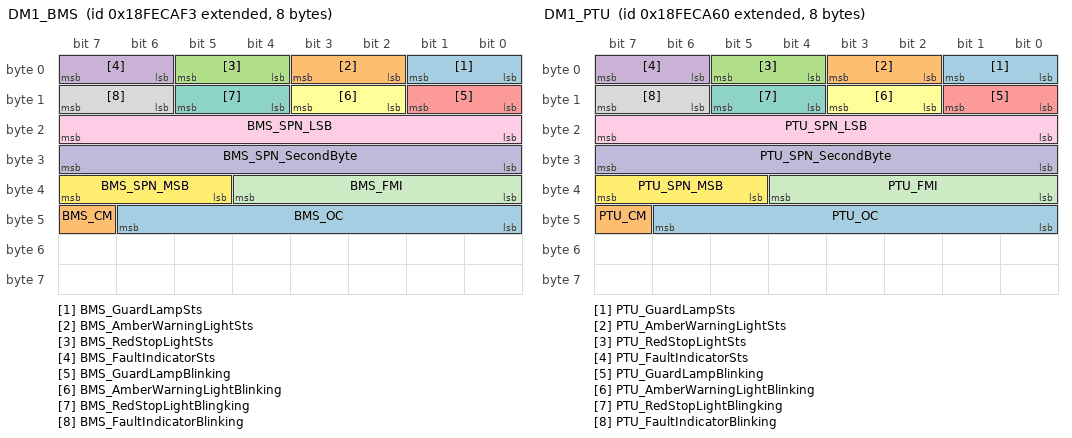
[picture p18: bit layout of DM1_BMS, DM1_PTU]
BO_ 2566834931 DM1_BMS: 8 CGW
 SG_ BMS_GuardLampSts : 0|2@1+ (1,0) [0|3] ""  ADU
 SG_ BMS_AmberWarningLightSts : 2|2@1+ (1,0) [0|3] ""  ADU
 SG_ BMS_RedStopLightSts : 4|2@1+ (1,0) [0|3] ""  ADU
 SG_ BMS_FaultIndicatorSts : 6|2@1+ (1,0) [0|3] ""  ADU
 SG_ BMS_GuardLampBlinking : 8|2@1+ (1,0) [0|3] ""  ADU
 SG_ BMS_AmberWarningLightBlinking : 10|2@1+ (1,0) [0|3] ""  ADU
 SG_ BMS_RedStopLightBlingking : 12|2@1+ (1,0) [0|3] ""  ADU
 SG_ BMS_FaultIndicatorBlinking : 14|2@1+ (1,0) [0|3] ""  ADU
 SG_ BMS_SPN_LSB : 16|8@1+ (1,0) [0|255] ""  ADU
 SG_ BMS_SPN_SecondByte : 31|8@0+ (1,0) [0|255] ""  Vector_XXX
 SG_ BMS_FMI : 32|5@1+ (1,0) [0|31] ""  ADU
 SG_ BMS_SPN_MSB : 37|3@1+ (1,0) [0|7] ""  ADU
 SG_ BMS_OC : 40|7@1+ (1,0) [1|126] ""  ADU
 SG_ BMS_CM : 47|1@1+ (1,0) [0|1] ""  ADU

BO_ 2566834784 DM1_PTU: 8 CGW
 SG_ PTU_GuardLampSts : 0|2@1+ (1,0) [0|3] ""  ADU
 SG_ PTU_AmberWarningLightSts : 2|2@1+ (1,0) [0|3] ""  ADU
 SG_ PTU_RedStopLightSts : 4|2@1+ (1,0) [0|3] ""  ADU
 SG_ PTU_FaultIndicatorSts : 6|2@1+ (1,0) [0|3] ""  ADU
 SG_ PTU_GuardLampBlinking : 8|2@1+ (1,0) [0|3] ""  ADU
 SG_ PTU_AmberWarningLightBlinking : 10|2@1+ (1,0) [0|3] ""  ADU
 SG_ PTU_RedStopLightBlingking : 12|2@1+ (1,0) [0|3] ""  ADU
 SG_ PTU_FaultIndicatorBlinking : 14|2@1+ (1,0) [0|3] ""  ADU
 SG_ PTU_SPN_LSB : 16|8@1+ (1,0) [0|255] ""  ADU
 SG_ PTU_SPN_SecondByte : 31|8@0+ (1,0) [0|255] ""  Vector_XXX
 SG_ PTU_FMI : 32|5@1+ (1,0) [0|31] ""  ADU
 SG_ PTU_SPN_MSB : 37|3@1+ (1,0) [0|7] ""  ADU
 SG_ PTU_OC : 40|7@1+ (1,0) [1|126] ""  ADU
 SG_ PTU_CM : 47|1@1+ (1,0) [0|1] ""  ADU

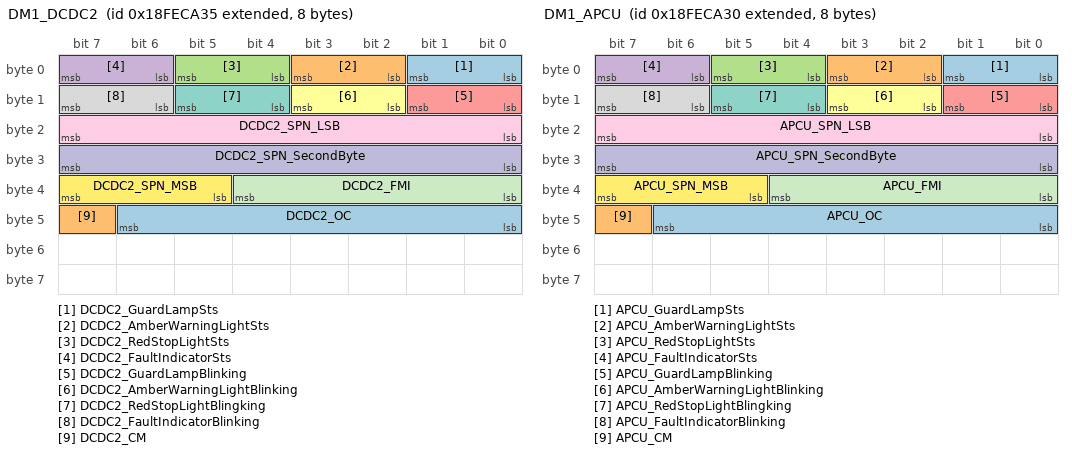
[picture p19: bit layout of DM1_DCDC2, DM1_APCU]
BO_ 2566834741 DM1_DCDC2: 8 CGW
 SG_ DCDC2_GuardLampSts : 0|2@1+ (1,0) [0|3] ""  ADU
 SG_ DCDC2_AmberWarningLightSts : 2|2@1+ (1,0) [0|3] ""  ADU
 SG_ DCDC2_RedStopLightSts : 4|2@1+ (1,0) [0|3] ""  ADU
 SG_ DCDC2_FaultIndicatorSts : 6|2@1+ (1,0) [0|3] ""  ADU
 SG_ DCDC2_GuardLampBlinking : 8|2@1+ (1,0) [0|3] ""  ADU
 SG_ DCDC2_AmberWarningLightBlinking : 10|2@1+ (1,0) [0|3] ""  ADU
 SG_ DCDC2_RedStopLightBlingking : 12|2@1+ (1,0) [0|3] ""  ADU
 SG_ DCDC2_FaultIndicatorBlinking : 14|2@1+ (1,0) [0|3] ""  ADU
 SG_ DCDC2_SPN_LSB : 16|8@1+ (1,0) [0|255] ""  ADU
 SG_ DCDC2_SPN_SecondByte : 31|8@0+ (1,0) [0|255] ""  Vector_XXX
 SG_ DCDC2_FMI : 32|5@1+ (1,0) [0|31] ""  ADU
 SG_ DCDC2_SPN_MSB : 37|3@1+ (1,0) [0|7] ""  ADU
 SG_ DCDC2_OC : 40|7@1+ (1,0) [1|126] ""  ADU
 SG_ DCDC2_CM : 47|1@1+ (1,0) [0|1] ""  ADU

BO_ 2566834736 DM1_APCU: 8 CGW
 SG_ APCU_GuardLampSts : 0|2@1+ (1,0) [0|3] ""  ADU
 SG_ APCU_AmberWarningLightSts : 2|2@1+ (1,0) [0|3] ""  ADU
 SG_ APCU_RedStopLightSts : 4|2@1+ (1,0) [0|3] ""  ADU
 SG_ APCU_FaultIndicatorSts : 6|2@1+ (1,0) [0|3] ""  ADU
 SG_ APCU_GuardLampBlinking : 8|2@1+ (1,0) [0|3] ""  ADU
 SG_ APCU_AmberWarningLightBlinking : 10|2@1+ (1,0) [0|3] ""  ADU
 SG_ APCU_RedStopLightBlingking : 12|2@1+ (1,0) [0|3] ""  ADU
 SG_ APCU_FaultIndicatorBlinking : 14|2@1+ (1,0) [0|3] ""  ADU
 SG_ APCU_SPN_LSB : 16|8@1+ (1,0) [0|255] ""  ADU
 SG_ APCU_SPN_SecondByte : 31|8@0+ (1,0) [0|255] ""  Vector_XXX
 SG_ APCU_FMI : 32|5@1+ (1,0) [0|31] ""  ADU
 SG_ APCU_SPN_MSB : 37|3@1+ (1,0) [0|7] ""  ADU
 SG_ APCU_OC : 40|7@1+ (1,0) [1|126] ""  ADU
 SG_ APCU_CM : 47|1@1+ (1,0) [0|1] ""  ADU

BO_ 2632777552 TPCM_BAM_EPB: 8 CGW

BO_ 2632712016 TPDT_EPB: 8 CGW

BO_ 2632777483 TPCM_BAM_EBS: 8 CGW

BO_ 2632711947 TPDT_EBS: 8 CGW

BO_ 2632777491 TPCM_EPS: 8 CGW

BO_ 2632711955 TPDT_EPS: 8 CGW

BO_ 2632777505 TPCM_BAM: 8 CGW

BO_ 2632711969 TPDT: 8 CGW

BO_ 2632777523 TP_CM_BAM: 8 CGW

BO_ 2632711987 TP_DT: 8 CGW

BO_ 2632777715 TPCM_BAM_BMS: 8 CGW

BO_ 2632712179 TPDT_BMS: 8 CGW

BO_ 2632777511 TPCM_BAM_HCU: 8 CGW

BO_ 2632711975 TPDT_HCU: 8 CGW

BO_ 2632777568 TPCM_BAM_PTU: 8 CGW

BO_ 2632712032 TPDT_PTU: 8 CGW

BO_ 2632777525 TPCM_BAM_DCDC2: 8 CGW

BO_ 2632711989 TPDT_DCDC2: 8 CGW

BO_ 2632777520 TPCM_BAM_APCU: 8 CGW

BO_ 2632711984 TPDT_APCU: 8 CGW

CM_ BO_ 2566844672 "Vehicle Speed 4/4. Cruise control vehicle speed.
Bosch AS need vehicle speed in ASIL D, therefore 2 sources with ASIL B or 4 sources with ASIL A should be available in the vehicle.";
CM_ SG_ 2566844672 ParkingBrakeSwitch "Switch signal which indicates when the parking brake is set.In general the switch actuated by theoperator's park brake control, whether a pedal, lever or other control mechanism.";
CM_ SG_ 2566844672 CruiseCtrlPauseSwitch "Switch signal which indicates the position of the Cruise Control Pause Switch used on Remote CruiseControl applications.";
CM_ SG_ 2566844672 WheelBasedVehicleSpeed "Speed of the vehicle as calculated from wheel or tailshaft speed.";
CM_ SG_ 2566844672 CruiseCtrlActive "Cruise control is switched on. It is not ensured that the engine is controlled by cruise control, as in thecase of a large driver's demand the engine is controlled by the driver while cruise control is active(maximum selection of cruise control and driver's demand). The cruise control is set to 0 if a switchoff condition occurs.";
CM_ SG_ 2566844672 CruiseCtrlEnableSwitch "Switch signal which indicates that it is possible to manage the cruise control function.
00 - Cruise control disabled
01 - Cruise control enabled
10 - Error
11 - NA";
CM_ SG_ 2566844672 BrakeSwitch "指示驾驶员操纵的制动脚踏板被踩下。这个制动脚踏板是控制车辆的服务制动(全车辆制动，不是停车制动)。为了保证传动系统的安全，必须在物理制动部件被激活之前启动开关(即在摩擦刹车激活之前断开巡航控制功能)。
00 - Brake pedal released
01 - Brake pedal depressed
10 - Error
11 - Not Available";
CM_ SG_ 2566844672 ClutchSwitch "指示离合器踏板被踩下的开关信号。为了保证传动系统的安全，离合器开关必须在离合器打开前设置(巡航控制功能)。
00 - Clutch pedal released
01 - Clutch pedal depressed
10 - Error
11 - Not available";
CM_ SG_ 2566844672 z_CruiseCtrlSetSwitch "Switch signal of the cruise control activator which indicates that the activator is in the position [set].
00 - Cruise control activator not in the position [set]
01 - Cruise control activator in position [set]
10 - Error
11 - NA";
CM_ SG_ 2566844672 CruiseCtrlResumeSwitch "Switch signal of the cruise control activator which indicates that the activator is in the position resume
00 - Cruise control activator not in the position  [resume]
01 - Cruise control activator in position [resume]
10 - Error
11 - NA";
CM_ SG_ 2566844672 CruiseCtrlSetSpeed "Value of set (chosen) velocity of velocity control system.  See SPN 6809 for an alternate resolution.
If an algorithm that can modify the cruise control set point exists in the system, such as Predictive Cruise Control or Adaptive Cruise Control, ...";
CM_ SG_ 2566844672 PTOGovernorState "This parameter is used to indicate the current state or mode of operation by the power takeoff (PTO) governor.  In lieu of support for PTO Drive Engagement parameters, this parameter may represent the status of a PTO drive.  The broadcasting device ...";
CM_ SG_ 2566844672 CruiseCtrlStates "This parameter is used to indicate the current state, or mode, of operation by the cruise control device.  This is a status parameter.
000 - Off/Disabled
001 - Hold
010 - Accelerate
011 - Decelerate
100 - Resume
101 - Set
110 - Accelerator …";
CM_ SG_ 2565866755 SelectedGear "The gear that the transmission will attempt to achieve during the current shift if a shift is in progress,or the next shift if one is pending (i.e., waiting for torque reduction to initiate the shift).Negativevalues are reverse gears positive values are forward gears zero is neutral 251 (0xFB) is park";
CM_ SG_ 2565866755 ActualGearRatio "Actual ratio of input shaft speed to output shaft speed.";
CM_ SG_ 2565866755 CurrentGear "The gear currently engaged in the transmission or the last gear engaged while the transmission is inthe process of shifting to the new or selected gear. Transitions toward a destination gear will not beindicated. Once the selected gear has been engaged then Current Gear will reflect that gear.Negativevalues are reverse gears positive values are forward gears zero is neutral 251 (0xFB) is park";
CM_ SG_ 2566834768 EPB_GuardLampSts "保护灯状态";
CM_ SG_ 2566834768 EPB_AmberWarningLightSts "琥珀色警示灯状态";
CM_ SG_ 2566834768 EPB_RedStopLightSts "红色停止灯状态";
CM_ SG_ 2566834768 EPB_FaultIndicatorSts "故障指示灯状态";
CM_ SG_ 2566834768 EPB_SPN_LSB "故障SPN的8个最低有效位（CM=0）
（第8位是最高有效位）";
CM_ SG_ 2566834768 EPB_SPN_SecondByte "故障SPN的第二字节（CM=0）
（第8位是最高有效位）";
CM_ SG_ 2566834768 EPB_FMI "FMI用于定义对SPN标识的子系统检测到的故障的类型（第5位是最高有效位）";
CM_ SG_ 2566834768 EPB_SPN_MSB "SPN， 3个最高有效位
（第8位是最高有效位）";
CM_ SG_ 2566834768 EPB_OC "故障发生次数
标识该故障由当前故障转变为历史故障的次数，如果故障发生次数不可知则全置位1";
CM_ SG_ 2566834768 EPB_CM "故障SPN转换方式（CM）";
CM_ BO_ 2566863952 "Electronic Parking Brake 1";
CM_ SG_ 2566863952 PressureofsprbrkchamberofEPB "Pressure of spring brake chamber of EPBEPB弹簧制动气室的压力";
CM_ SG_ 2566863952 ReasonforinhibitionofEPBrelease "Reason for inhibition of EPB releaseEPB释放抑制的原因";
CM_ SG_ 2566863952 ReasonforinhibitionofEPBapply "Reason for inhibition of EPB apply";
CM_ SG_ 2566863952 AmberWarningLampStatus "黄色警示灯状态";
CM_ SG_ 2566863952 StateofinhibitionofEPBrelease "State of inhibition of EPB releaseEPB释放抑制状态";
CM_ SG_ 2566863952 StateofEPB "FE: Error
FF: Not available";
CM_ SG_ 2566863952 WorkingmodeofEPB "FE: Error
FF: Not available";
CM_ SG_ 2566863952 Trailertestactivationstate "Trailer test activation state拖车试验激活状态";
CM_ SG_ 2566863952 StateofinhibitionofEPBapply "FE: Error
FF: Not available";
CM_ SG_ 2566863952 EPBHCUinparkingstate "EPB HCU in parking state";
CM_ SG_ 2566834699 ABS_GuardLampSts "保护灯状态";
CM_ SG_ 2566834699 ABS_AmberWarningLightSts "琥珀色警示灯状态";
CM_ SG_ 2566834699 ABS_RedStopLightSts "红色停止灯状态";
CM_ SG_ 2566834699 ABS_FaultIndicatorSts "故障指示灯状态";
CM_ SG_ 2566834699 ABS_SPN_LSB "故障SPN的8个最低有效位（CM=0）
（第8位是最高有效位）";
CM_ SG_ 2566834699 ABS_SPN_SecondByte "故障SPN的第二字节（CM=0）
（第8位是最高有效位）";
CM_ SG_ 2566834699 ABS_FMI "FMI用于定义对SPN标识的子系统检测到的故障的类型（第5位是最高有效位）";
CM_ SG_ 2566834699 ABS_SPN_MSB "SPN， 3个最高有效位
（第8位是最高有效位）";
CM_ SG_ 2566834699 ABS_OC "故障发生次数
标识该故障由当前故障转变为历史故障的次数，如果故障发生次数不可知则全置位1";
CM_ SG_ 2566834699 ABS_CM "故障SPN转换方式（CM）";
CM_ BO_ 2565865739 "Electronic　Brake Controller#1";
CM_ SG_ 2565865739 ASREngCtrlActive "State signal which indicates that ASR engine control has been commanded to be active. Active means that ASR actually tries tocontrol the engine. This state signal is independent of other control commands to the engine (e.g., from the transmission) whichmay have higher priority.
状态信号，指示ASR引擎控制已被命令激活。Active意味着ASR实际上试图控制引擎。这种状态信号独立于其他可能具有更高优先级的引擎控制命令(例如，来自传动系)。";
CM_ SG_ 2565865739 ASRBrakeCtrlActive "State signal which indicates that ASR brake control is active. Active means that ASR actually controls wheel brake pressure at one or more wheels of the driven axle(s).
状态信号，指示ASR制动控制激活。Active意味着ASR实际上控制一个或多个车轮的从动轴的制动压力。";
CM_ SG_ 2565865739 ABSActive "State signal which indicates that the ABS is active. The signal is set active when wheel brake pressure actually starts to bemodulated by ABS and is reset to passive when all wheels are in a stable condition for a certain time. The signal can also be setactive when driven wheels are in high slip (e.g., caused by retarder). Whenever the ABS system is not fully operational (due to adefect or during off-road ABS operation) , this signal is only valid for that part of the system that is still working. When ABS";
CM_ SG_ 2565865739 EBSBrakeSwitch "Switch signal which indicates that the brake pedal is being pressed.The EBS brake switch is independent of the brake light switchand has no provisions for external connections.
指示正在踩下刹车踏板的开关信号。EBS制动开关独立于制动灯开关，没有外部连接的规定。";
CM_ SG_ 2565865739 BrakePedalPos "Ratio of brake pedal position to maximum pedal position. Used for electric brake applications. 0% means no braking.Also whenthere are two brake pedals on the machine,the maximum of the two should be transmitted for Brake Pedal Position.
制动踏板位置百分比";
CM_ SG_ 2565865739 ABSOffroadSwitch "Switch signal which indicates the position of the ABS off-road switch.
ABS越野开关";
CM_ SG_ 2565865739 ASROffroadSwitch "Switch signal which indicates the position of the ASR off-road switch.";
CM_ SG_ 2565865739 ASRHillHolderSwitch "Switch signal which indicates the position of the ASR 'hill holder' switch.
ASR 坡路防滑开关";
CM_ SG_ 2565865739 ABSFullyOperational "Signal which indicates whether an ABS system is fully operational or whether its functionality is reduced by a defect or by anintended action (e.g., by activation of an ABS-off-road switch or during special diagnostic procedures). There are cases where thesignal is necessary to fulfill legal regulations for special applications (e.g., switching off integrated retarders).
表明ABS系统是否完全运行或其功能是否因缺陷或预期操作而降低的信号(例如，通过激活ABS-越野开关或在特殊诊断过程中)。在某些情况下，信号是必要的，以满足特殊应用的法律规定(例如，关闭集成的缓速器)。";
CM_ SG_ 2565865739 EBSRedWarningSignal "This parameter commands the EBS red optical warning signal.
EBS红色警报";
CM_ SG_ 2565865739 ABS_EBSAmberWarningSignal "This parameter commands the ABS/EBS amber/yellow optical warning signal.
ABS_EBS琥珀色警报灯";
CM_ SG_ 2565865739 ATC_ASRInfoSignal "This parameter commands the ATC/ASR driver information signal, for example a dash lamp.
此参数命令ATC/ASR驾驶员指示信息信号，如仪表灯。";
CM_ SG_ 2565865739 SrcAddrssOfCntrllngDvcFrBrkeCtrl "The source address of the SAE J1939 device currently controlling the brake system.
EBS制动控制源地址";
CM_ SG_ 2565865739 TrailerMountedABSWarning "This parameter commands the tractor-mounted trailer ABS optical warning signal.
挂车ABS报警信号";
CM_ SG_ 2566831883 Front_Axle_Speed "前轴平均速度";
CM_ SG_ 2566831883 Relative_Speed_FrontAxle_LeftWhe "前轴左侧轮相对于前轴的速度";
CM_ SG_ 2566831883 Relative_Speed_FrontAxle_RightWh "前轴右侧轮相对于前轴的速度";
CM_ SG_ 2566831883 Relative_Speed_RearAxle1_LeftWhe "后轴左侧轮相对于前轴的速度";
CM_ SG_ 2566831883 Relative_Speed_RearAxle1_RightWh "后轴右侧轮相对于前轴的速度";
CM_ SG_ 2566831883 Relative_Speed_RearAxle2_LeftWhe "第三轴左侧轮相对于前轴的速度";
CM_ SG_ 2566831883 Relative_Speed_RearAxle2_RightWh "第三轴右侧轮相对于前轴的速度";
CM_ BO_ 2566767627 "Electronic Brake Controller 5
Used for information on brake control.";
CM_ SG_ 2566767627 BrakeTempWarning "This parameter indicates if the temperature in the service brakes exceeds a certain value. It can be used for a warning information for the driver. The temperature warning value is vehicle manufacturer specific.
制动器高温警报";
CM_ SG_ 2566767627 HaltBrakeMode "Signal which indicates the current mode of the halt brake function.
停车制动";
CM_ SG_ 2566767627 HillHolderMode "Signal which indicates the current mode of the hill holder function.
坡路防滑模式";
CM_ SG_ 2566767627 FoundationBrakeUse "This parameter indicates if the brake system presently uses the foundation brakes.
当前制动系统是否使用基础制动。";
CM_ SG_ 2566767627 XBRSystemState "This parameter indicates which external brake control is allowed.
该参数表示允许哪个外部制动控制。";
CM_ SG_ 2566767627 XBRActiveCtrlMode "This parameter indicates which XBR Control Mode is executed by the brake system.
该参数表示制动系统执行哪种XBR控制模式。";
CM_ SG_ 2566767627 XBRAccelerationLimit "The brake system may temporarily or generally limit the maximum brake performance available for external systems. A temporarylimit may be nessary due to high brake temperature; a general limit may be defined by the vehicle manufacturer,The actual limit iscommunicated to the external systems that request braking.
制动系统可能暂时或一般地限制外部系统的最大制动性能。由于制动温度过高，可能需要临时限制;汽车制造商可能会定义一个通用限值，例如，由于责任原因，限值为-2.5 m/s?。实际限制是传达到请求制动的外部系统。此限制仅在XBR优先级1~3中有效。它被指定为相对于道路的绝对加速度。";
CM_ SG_ 2566767627 EmergencyBrakingActive "Signal which indicates an emergency braking situation with high deceleration values. This signal can be used to activate thehazard lights to indicate other road users to the rear and front of the vehicle that a high retardation force has been applied to thevehicle relative to the prevailing road conditions.
指示高减速值紧急制动状况的信号(参考ECE Regulation 13 paragraph 5.2.1.31)。此信号可用于激活危险警报灯(参考ECEECE Regulation 13 paragraph 5.2.1.31)";
CM_ BO_ 2565868307 "EPS Output - PGN which indicates the actual angle and the status of a steerable axle";
CM_ SG_ 2565868307 ActualInnerWheelSteerAngle "Signal which indicates the actual inner wheel steering angle.  The steering angle is the angle of wheel turn relative to the vehicle x-axis (yaw angle of inner wheel). See Figure SPN2927_A for explanation of positive and negative angles. 
指示实际内轮转向角度的信号。转向角度是车轮相对于车辆x轴的角度(内车轮的偏航角)。左负右正";
CM_ SG_ 2565868307 AxleLocation "To identify to which of several similar devices (such as tires or fuel tanks) the information applies.The low order 4 bits represent a position number, counting left to right when facing in the direction of normal vehicle travel(forward).The high order 4 bits represent a position number, counting front to back on the vehicle.The value FFh indicates notavailable.It is recommended that output devices add 1 to the position number (range 1 to 15, not 0 to 14) for use by drivers and servicetechnicians. Examples
以确定几个类似的设备(如轮胎或油箱)中的哪一个适用该信息。
低阶4位代表一个位置号，当面对正常车辆行驶(前进)的方向时，从左到右计算。高阶4位代表一个位置号，在车辆上从前到后计算。
0xFF表示不可用。
建议输出设备在位置号上加1(范围为1 ~ 15，而不是0 ~ 14)，以便司机和维修人员使用。例如:0x00位置的轮胎压力是左前胎。
在3轴牵引车(3轴，4胎)上，0x23位置的胎压应该在两侧都有双轴的后外侧。";
CM_ SG_ 2565868307 StatusOfSteerAxle "A signal which indicates different states of the steering axle";
CM_ SG_ 2565868307 SteerableLiftAxleLoweringInhibit "A signal which indicates if lowering of lifted axle is allowed or inhibited.
指示已生气的转向轴是允许还是禁止下降。";
CM_ SG_ 2565868307 SteerType "Indicates the different types of steering systems (ref. ECE Regulation 79 paragraph 2.5)
指示不同类型的转向系统
0-Main steering system主要转向（决定车的前进方向，本项目默认1）
1-Auxiliary steering equipment次要转向
2-E：Reserved for Assignment by SAE
F:不可用";
CM_ SG_ 2565868307 TypeOfSteerForces "Type of Steering Forces (Ref. ECE Regulation 79 paragraph 2.5)
转向力类型";
CM_ SG_ 2565868307 TypeOfSteerTrans "Type of Steering Transmission (Ref. ECE Regulation 79 paragraph 2.6)
转向传动系类型";
CM_ SG_ 2566811659 PoweredVehicleWeight "Total mass imposed by the tires of the powered vehicle on the road surface. Does not include the";
CM_ SG_ 2566811659 GrossCombinationVehicleWeight "The total weight of the truck and all attached trailers.";
CM_ BO_ 2565867787 "Vehicle Dynamic StabilityControl 2";
CM_ SG_ 2565867787 SteerWheelAngle "The main operator`s steering wheel angle (on the steering column, not the actual wheel angle). The vehicle being steered to theleft (counterclockwise) results in a positive steering wheel angle.
驾驶位方向盘角度(在转向柱上，不是实际的车轮角度)。左正右负。";
CM_ SG_ 2565867787 SteerWheelTurnCounter "Indicates number of steering wheel turns, absolute position or relative position at ignition on. Positive values indicate left turns.
指示方向盘转动圈数，点火时的绝对位置或相对位置";
CM_ SG_ 2565867787 SteerWheelAngleSensorType "Indicates whether the steering wheel angle sensor is capable of absolute measuring of the number of steering wheel turns or not (relative measuring to position at ignition on).
指示方向盘转角传感器是否能够绝对测量方向盘转动次数(相对于点火位置)。";
CM_ SG_ 2565867787 YawRate "Indicates the rate of rotation about the vertical axis (i.e. the z-axis).  A positive yaw rate signal results when the vehicle turns counter-clockwise.";
CM_ SG_ 2565867787 LateralAcceleration "Indicates a lateral acceleration of the vehicle (the component of vehicle acceleration vector along the Y-axis). A positive lateral acceleration signal results when the vehicle is accelerated to the left.";
CM_ SG_ 2565867787 LongitudinalAcceleration "Indicates the longitudinal acceleration of the vehicle. A positive longitudinal acceleration signal results when the vehicle speedincreases, regardless of driving the vehicle forward or backward.";
CM_ BO_ 2365473062 "Lighting Command
The lighting command message has been defined as a global message from the tractor to all lighting controllers on the tractor and attached implements.  Separate messages are provided for tractor and implement work and driving ...";
CM_ SG_ 2365473062 RunningLightCmd_1 "Command to activate or de-activate the tractor or powered vehicle running lights.  Usually only used for on road vehicles.";
CM_ SG_ 2365473062 LowBeamHeadLightCmd_1 "Command to activate or de-activate the tractor low beam head light lamps.";
CM_ SG_ 2365473062 HighBeamHeadLightCmd_1 "Command to activate or de-activate the tractor high beam head light lamps.";
CM_ SG_ 2365473062 TractorFrontFogLightsCmd_1 "Command to activate or de-activate tractor front fog lights.";
CM_ SG_ 2365473062 RightTurnSignalLightsCmd_1 "Command to activate or de-activate right turn signal lights on the tractor and all connected implements";
CM_ SG_ 2365473062 LeftTurnSignalLightsCmd_1 "Command to activate or de-activate left turn signal lights on the tractor and all connected implements";
CM_ SG_ 2365473062 BackUpLightAndAlarmHornCmd_1 "Command to activate or de-activate the back up lights and/ or associated alarm if required";
CM_ SG_ 2365473062 implement_marker_light_command_1 "Command to activate or de-activate implement front position lights, rear red tail lights, side amber running lights,licenseplate lights and instrument and switch back lights.激活或关闭执行前位置灯，后红色尾灯，侧面琥珀色行驶灯，车牌灯和仪器和开关后灯命令。";
CM_ SG_ 2365473062 RearFogLightCmd_1 "Command to activate or de-activate tractor or implement rear fog lights.";
CM_ BO_ 2365473057 "Lighting Command
The lighting command message has been defined as a global message from the tractor to all lighting controllers on the tractor and attached implements.  Separate messages are provided for tractor and implement work and driving ...";
CM_ SG_ 2365473057 RunningLightCmd "Command to activate or de-activate the tractor or powered vehicle running lights.  Usually only used for on road vehicles.";
CM_ SG_ 2365473057 LowBeamHeadLightCmd "Command to activate or de-activate the tractor low beam head light lamps.";
CM_ SG_ 2365473057 HighBeamHeadLightCmd "Command to activate or de-activate the tractor high beam head light lamps.";
CM_ SG_ 2365473057 TractorFrontFogLightsCmd "Command to activate or de-activate tractor front fog lights.";
CM_ SG_ 2365473057 RightTurnSignalLightsCmd "Command to activate or de-activate right turn signal lights on the tractor and all connected implements";
CM_ SG_ 2365473057 LeftTurnSignalLightsCmd "Command to activate or de-activate left turn signal lights on the tractor and all connected implements";
CM_ SG_ 2365473057 BackUpLightAndAlarmHornCmd "Command to activate or de-activate the back up lights and/ or associated alarm if required";
CM_ SG_ 2365473057 CenterStopLightCmd "Command to activate or de-activate the tractor and implement center stop light";
CM_ SG_ 2365473057 implement_marker_light_command "Command to activate or de-activate implement front position lights, rear red tail lights, side amber running lights,licenseplate lights and instrument and switch back lights.激活或关闭执行前位置灯，后红色尾灯，侧面琥珀色行驶灯，车牌灯和仪器和开关后灯命令。";
CM_ SG_ 2365473057 RearFogLightCmd "Command to activate or de-activate tractor or implement rear fog lights.";
CM_ SG_ 2365473057 driver_side_cab_dome_light "Switch signal which indicates the status of “Driver Side Reading Light“. It is the nonlocking switch, the signal valueshould be 1 during the switch be pressed.";
CM_ SG_ 2365473057 passenger_side_cab_dome_light "Switch signal which indicates the status of “Passenger Side Cab Dome Light“. It is the nonlocking switch, the signalvalue should be 1 during the switch be pressed.";
CM_ BO_ 2566759713 "Door Control 2
Used for door information.";
CM_ SG_ 2566759713 LockStatusofDoor1_Driver "Signal which indicates lock status of driver door";
CM_ SG_ 2566759713 OpenStatusofDoor1_Driver "Signal which indicates open status of driver door.";
CM_ SG_ 2566759713 LockStatusofDoor2_Passenger "Signal which indicates lock status of passenger door.";
CM_ SG_ 2566759713 OpenStatusofDoor2_Passenger "Signal which indicates open status of passenger door.";
CM_ SG_ 2365578991 MotorWorkingMode "电机工作模式（实际工作模式）
电机有四种工作状态：自由随动状模式、扭矩控制模式、转速控制模式和转子零位标定。
要求电机处于自由随动状态运行时，电机的输出扭矩为零，即不能电动也不能发电，电耗降至极小值。要求具有快速进入电动及发电的响应速度。";
CM_ SG_ 2365578991 MotorRotateDirection "电机旋转方向（实际转向）：
00 无旋转方向输出（转速在±10rpm以内无旋转方向
输出）；
01 正向：整车前进时电机旋转方向；
10 反向：整车后退时电机旋转方向；
11 不可用。";
CM_ SG_ 2365578991 MotorSts "电机系统状态
0x0:表示低压上电完成，但高压电未建立的状态；
0x1:表示低压上电完成，高压上电过程中；
0x2:表示高、低压上电都完成后的状态，无扭矩输出的随动状态；
0x3:表示电机系统处于正常响应指令输出的牵引或制动状态；
0x4:表示电机系统处于限功率响应指令输出的牵引或制动状态，折扣输出；
0x5:表示电机系统发生故障；
0x6:表示高压下电过程中；
0xF:表示除以上状态以外的无效状态。";
CM_ SG_ 2365578991 HighPrecisionActualMotorTrq "表示实际电机扭矩的小数部分，与信号＜电机扭矩＞共同组成实际电机扭矩。如果b3为1表示该参数不可用。当b3为0时，b0到b2用于表示电机扭矩的高精度部分，表示精度是0.125%，表示范围是0%-0.875%。";
CM_ SG_ 2365578991 HighPrecisionMaxMotorTrq "表示电机可用最大电动高精度转矩的小数部分，与信号＜电机可用最大电动转矩＞共同组成电机可用电动扭矩。如果b3为1表示该参数不可用。当b3为0时，b0到b2用于表示电机扭矩的高精度部分，表示精度是0.125%，表示范围是0%-0.875%。";
CM_ SG_ 2365578991 MotorTrq "表示电机扭矩。正值表示要求电机处于电动状态；负值表示要求电机处于发电状态。信号以扭矩百分比形式来表示，100.0%代表电机最大输出扭矩，最大输出扭矩是不随转速变化的常数（本项目园区清扫车为450Nm）。＜电机扭矩＞为实际电机扭矩的整数部分，同＜高精";
CM_ SG_ 2365578991 MotorMaxTrq "表示电机可用最大电动转矩。实际取值范围为0-125%。信号以扭矩百分比形式来表示，100.0%代表电机可用最大电动转矩，电动转矩是不随转速变化的常数。＜电机可用最大电动转矩＞为电机可用最大电动转矩的整数部分，同＜电机可用最大电动高精度转矩＞共同组成电机可用最大电动转矩。";
CM_ SG_ 2365578991 MotorSpd "表示电机实际转速。
实际的物理值范围是0rpm-7000rpm。
实际的精度是1rpm。";
CM_ SG_ 2365578991 HighVoltOffSts "该信号是对电机高压下电请求信号的反馈。取值1表示允许下电，则整车控制器将切下电机母线侧的高压继电器。";
CM_ SG_ 2365578991 MotorDischargeSts "表示电机主动放电状态。
00: 主动放电未启动，未接收到电机主动放电命令或者未启动主动放电
01：主动放电进行，执行主动放电过程中
10：主动放电完成，母线电容电压在3s内降到60V以内，
主动放电完成
11：主动放电退出，执行主动放电过程因故障退出";
CM_ SG_ 2365578991 MotorFaliureSts "电机故障状态反馈。
三级故障为最严重故障。";
CM_ SG_ 2365578991 MCU1_RollingCounter "报文计数器用于检测由于报文发送者故障导致重复发生同一帧报文。报文接收者可以使用报文计数器检测到这种情况。报文发送者在每个报文发送周期令报文计数器增1，报文计时器从0开始计数直到15，然后再从0开始计数。";
CM_ SG_ 2365578991 MCU1_Checksum "报文校验和用于验证从发送设备到接收设备的信号传输路径。校验和是下述数据的和：报文ID由高字节至低字节的和、数据区前7个字节以及报文计数器。校验和计算公式如下：
校验和 = (字节1 + 字节2 + 字节3 + 字节4 + 字节5 +字节6 + 字节7 + 报文计数器 & 0x0F + 报文ID低字节+ 报文ID中低字节 + 报文ID中高字节 + 报文ID高字节)
校验和 = ((校验和 >> 4) + 校验和) & 0x0F";
CM_ SG_ 2566834707 EPS_GuardLampSts "保护灯状态";
CM_ SG_ 2566834707 EPS_AmberWarningLightSts "琥珀色警示灯状态";
CM_ SG_ 2566834707 EPS_RedStopLightSts "红色停止灯状态";
CM_ SG_ 2566834707 EPS_FaultIndicatorSts "故障指示灯状态";
CM_ SG_ 2566834707 EPS_SPN_LSB "故障SPN的8个最低有效位（CM=0）
（第8位是最高有效位）";
CM_ SG_ 2566834707 EPS_SPN_SecondByte "故障SPN的第二字节（CM=0）
（第8位是最高有效位）";
CM_ SG_ 2566834707 EPS_FMI "FMI用于定义对SPN标识的子系统检测到的故障的类型（第5位是最高有效位）";
CM_ SG_ 2566834707 EPS_SPN_MSB "SPN， 3个最高有效位
（第8位是最高有效位）";
CM_ SG_ 2566834707 EPS_OC "故障发生次数
标识该故障由当前故障转变为历史故障的次数，如果故障发生次数不可知则全置位1";
CM_ SG_ 2566834707 EPS_CM "故障SPN转换方式（CM）";
CM_ SG_ 2566910227 ColumnTorque "Column torque measured by the torque sensor.Value type: Signed.CAN Range: 0xD800 (Min), 0x2800 (Max).
方向盘扭矩";
CM_ SG_ 2566910227 ColumnVelocity "Column velocity measured by the motor encoder. Value type: Signed.CAN Range: 0xEC00 (Min), 0x1400 (Max).
方向盘转速";
CM_ SG_ 2566910227 PullCompensation "The purpose of pull compensation is to act as an integrator to remove any average torque on the handwheel. This is necessary toallow the handwheel to be held off-center for a prolonged period of time without handwheel torque.
Value type: Signed.CAN Range: 0xB380 (Min), 0x4C80 (Max).
拉力补偿的目的是作为一个积分器去除方向盘上的任何平均扭矩。这是必要的，以允许方向盘在没有手动扭矩的情况下长时间保持偏心。";
CM_ SG_ 2566910227 ColumnTorqueQF "Quality Factor for Column Torque signal. Valid (1) or invalid (0). Value type: Unsigned.
品质因数";
CM_ SG_ 2566910227 ColumnVelocityQF "Quality Factor for Column Velocity signal. Valid (1) or invalid (0). Value type: Unsigned.";
CM_ SG_ 2566910227 IgnitionState "Ignition signal status, Ignition ON (1), Ignition OFF (0). Value type: Unsigned.";
CM_ SG_ 2566910227 HandsOffDetected "Hands Off Detected status, ON (1), OFF (0). Value type: Unsigned.";
CM_ SG_ 2566910227 HandsOnDetected "Hands On Detected status, ON (1), OFF (0). Value type: Unsigned.";
CM_ SG_ 2566910227 MessageChecksum_EPS1 "the high nibble and the low nibble of the sum of the identifier, the first 7 data bytes and the 4 bit message counter. It is calculatedas follows:Checksum = (Byte1 + Byte2 + Byte3 + Byte4 + Byte5 + Byte6 + Byte7 + (message counter & 0x0F) + message ID low byte +message ID mid low byte + message ID mid high byte + message ID high byte)Checksum = ((Checksum >> 4) + Checksum) & 0x0F";
CM_ SG_ 2566910227 MessageCounter_EPS1 "Same as SPN 3689. The message counter is to verify the signal path from the demanding device to the steering controller. Thesupport of this parameter is mandatory.Note: The initial value of the 4 bit message counter for the first message during a driving cycle is arbitrary. In every followingmessage the counter is incremented by 1 (0 follows 15).";
CM_ SG_ 2566909971 AbsoluteSteerPosition "The absolute steering position measured by the angle sensor. Value type: Signed.CAN Range: 0xB380 (Min), 0x4C80 (Max).
方向盘绝对位置，左负右正";
CM_ SG_ 2566909971 ExtInputCmdEcho "This is an echo of the external input command. Input can be in Nm or Deg, depending on mode used. Value type: Signed. CANRange: 0xB380 (Min), 0x4C80 (Max).
外部输入的控制值";
CM_ SG_ 2566909971 StatusOrError "Each bit in this byte indicates a seperate status flag.
Bit 1 - SYSTEM_NEEDS_INITIAL_STARTING_POSITION
Bit 2 - INVAILID_OPERATING_MODE
Bit 3 - EXT_INPUT_COMMAND_ERROR
Bit 4 - VEHICLE_SPEED_MISSING
Bit 5 - COLUMN_DRIVE_IN_SLEEP_MODE
Bit 6 - MAXIMUM_MOTOR_TORQUE_ACHIEVED
Bit 7 - INTERNAL_COLUMN_DRIVE_ERROR
Error状态，每一位表示一个独立的Error状态：
bit 1:系统需初始化起始位置；
bit 2:无效的操作模式；
bit 3:外部输入指令错误；
bit 4:车速丢失；
bit 5:转向柱驱动处于睡眠模式；
bit 6:已达到电机最大扭矩；
bit 7:内部转向柱驱动错误";
CM_ SG_ 2566909971 ActualMode "The actual mode is ReAX working.";
CM_ SG_ 2566909971 RequestMode "This is an echo of the Request operating mode from PropB_FE.
对lcks_cmd控制报文的响应";
CM_ SG_ 2566909971 MessageChecksum_EPS2 "See EPS1";
CM_ SG_ 2566909971 MessageCounter_EPS2 "See EPS1";
CM_ SG_ 2566845491 Tire_Location "Identifies which tire is associated with the parametric data in this PGN.The low order 4 bits represent a position number, counting left to right when facing in the direction of normal vehicletravel (forward).The high order 4 bits represent a position number, counting front to back on the vehicle.The value 0xFF indicates not available.It is recommended that output devices add 1 to the position number (range 1 to 15, not 0 to 14) for use by drivers andservice technicians.Examples: Tire pressure for location 0x00 would be left front tire.Tire pressure for location 0x23 would be right outside rear rear on a 3-axle tractor with dual axle per side";
CM_ SG_ 2566845491 Tire_Pressure "Pressure at which air is contained in cavity formed by tire and rim.";
CM_ SG_ 2566845491 Tire_Temperature "Temperature at the surface of the tire sidewall.";
CM_ SG_ 2566845491 Tire_Status "Indicates the status of the tire.";
CM_ SG_ 2566845491 Extended_Tire_Pressure_Support "Defines the choice of using the tire pressure (TIRE1) or Extended Tire Pressure (TIRE2). The state value '01' indicatesthe extended tire pressure (Tire Pressure (Extended Range)) is used for the pressure data. Any other value indicates theextended tire pressure (Tire Pressure (Extended Range)) is not being used.";
CM_ SG_ 2566845491 Tire_AirLeakage_Rate "The pressure loss rate of a tire.";
CM_ SG_ 2566845491 TirePressureThresholdDetection "Signal indicating the pressure level of the tire. The levels defined represent different pressure conditions of the tire.";
CM_ SG_ 2566668851 Tire_Location "Identifies which tire is associated with the parametric data in this PGN.The low order 4 bits represent a position number, counting left to right when facing in the direction of normal vehicletravel (forward).The high order 4 bits represent a position number, counting front to back on the vehicle.The value 0xFF indicates not available.It is recommended that output devices add 1 to the position number (range 1 to 15, not 0 to 14) for use by drivers andservice technicians.Examples: Tire pressure for location 0x00 would be left front tire.Tire pressure for location 0x23 would be right outside rear rear on a 3-axle tractor with dual axle per side (3rd axle,4th tire).";
CM_ SG_ 2566668851 Tire_PressExtedRage "Pressure at which air is contained in cavity formed by tire and rim. See sigal 'Tire Pressure' for alternate tire pressurewith a lower range and coarser resolution";
CM_ SG_ 2566668851 RequiredTirePressure "The required tire pressure at which air is contained in cavity formed by tire and rim.This pressure of the tire is compensated to meet the specific physical environmental conditions (temperature) of the";
CM_ SG_ 2566897971 TireLocation "Identifies which tire is associated with the parametric data in this PGN.The low order 4 bits represent a position number, counting left to right when facing in the direction of normal vehicletravel (forward).The high order 4 bits represent a position number, counting front to back on the vehicle.The value 0xFF indicates not available.It is recommended that output devices add 1 to the position number (range 1 to 15, not 0 to 14) for use by drivers andservice technicians.Examples: Tire pressure for location 0x00 would be left front tire.Tire pressure for location 0x23 would be right outside rear rear on a 3-axle tractor with dual axle per side (3rd axle,4th tire).";
CM_ SG_ 2566897971 TireSensorMatchStatus "Identifies whether the tire sensor is matched or not.";
CM_ SG_ 2566897971 TireSensorSelfLearningStatus "Identifies the self learning status of tire sensor.";
CM_ SG_ 2566897971 TireSensorElectricalFault "Indicates the status of electrical fault on the tire sensor.";
CM_ SG_ 2566897971 TireTemperatureThresholdDetectio "Signal indicating the Temperature level of the tire. The levels defined represent differenttemperature conditions of the tire.";
CM_ SG_ 2566834739 TPMS_GuardLampSts "保护灯状态";
CM_ SG_ 2566834739 TPMS_AmberWarningLightSts "琥珀色警示灯状态";
CM_ SG_ 2566834739 TPMS_RedStopLightSts "红色停止灯状态";
CM_ SG_ 2566834739 TPMS_FaultIndicatorSts "故障指示灯状态";
CM_ SG_ 2566834739 TPMS_SPN_LSB "故障SPN的8个最低有效位（CM=0）
（第8位是最高有效位）";
CM_ SG_ 2566834739 TPMS_SPN_SecondByte "故障SPN的第二字节（CM=0）
（第8位是最高有效位）";
CM_ SG_ 2566834739 TPMS_FMI "FMI用于定义对SPN标识的子系统检测到的故障的类型（第5位是最高有效位）";
CM_ SG_ 2566834739 TPMS_SPN_MSB "SPN， 3个最高有效位
（第8位是最高有效位）";
CM_ SG_ 2566834739 TPMS_OC "故障发生次数
标识该故障由当前故障转变为历史故障的次数，如果故障发生次数不可知则全置位1";
CM_ SG_ 2566834739 TPMS_CM "故障SPN转换方式（CM）";
CM_ SG_ 2364539648 AcceleratorPedal1LowIdleSwitch "Switch signal which indicates the state of the accelerator pedal 1 low idle switch.";
CM_ SG_ 2364539648 AcceleratorPedalKickdownSwitch "Switch signal which indicates whether the accelerator pedal kickdown switch is opened or closed.";
CM_ SG_ 2364539648 AcceleratorPedalPosition "The ratio of actual accelerator pedal position to maximum pedal position. Although it is used as aninput to determine powertrain demand, it also provides anticipatory information to transmission andASR algorithms about driver actions";
CM_ SG_ 2364539648 PercentLoadAtCurrentSpeed "The ratio of actual engine percent torque (indicated) to maximum indicated torque available at thecurrent engine speed, clipped to zero torque during engine braking.";
CM_ SG_ 2348810282 OverrideCtrlMode_ACCE "The override control mode defines which sort of command is used.
发动机控制模式";
CM_ SG_ 2348810282 ReqSpdCtrlConditions_ACCE "This mode tells the engine control system the governor characteristics that are desired during speed control.
速度控制时用的
0x0:针对传动系统脱离和非锁定情况进行的瞬态优化
0x1:为传动系统脱离和非锁定条件优化的稳定性
0x2:针对传动系统啮合和/或处于锁定状态1的稳定性进行了优化
0x3:为传动系统啮合和/或处于锁定状态而优化的稳定性2";
CM_ SG_ 2348810282 OverrideCtrlModePriority_ACCE "This field is used as an input to the engine or retarder to determine thepriority of the Override Control Mode received in theTorque/Speed Control message (see PGN 0). The default is 11 (Low priority). It is not required to use the same priority duringthe entire override function. For example, the transmission can use priority 01 (High priority) during a shift, but can set thepriority to 11 (Low priority) at the end of the shift to allow traction control to also interact with the torque limit of the engine.
该字段被用作发动机或减速机的输入，以确定在转矩/速度控制消息中接收到的超驰控制模式的优先级(参见PGN 0)。默认值是11(低优先级)。在整个override函数中不需要使用相同的优先级。例如，变速器在换挡时可以使用优先级01(高优先级)，但在换挡结束时可以将优先级设置为11(低优先级)，以便牵引力控制也可以与发动机的扭矩限制相互作用。";
CM_ SG_ 2348810282 TorqReqOrTorqLimitReq_ACCE "Parameter provided to the engine or retarder in the torque/speed control message for controlling or limiting the output torque.Requested torque to the engine is measured in indicated torque as a percentage of reference engine torque. This is the enginetorque at which the engine is expected to operate if the torque control mode is active or the engine torque which the engine is notexpected to exceed if the torque limit mode is active
在转矩/速度控制信息中提供给发动机或减速机的参数，用于控制或限制输出转矩。要求的发动机转矩是用指示转矩作为参考发动机转矩的百分比来测量的。这是在转矩控制模式为Auto模式时发动机预期运行的发动机转矩，或在转矩限制模式为Auto模式时发动机预期不会超过的发动机转矩";
CM_ SG_ 2348810282 TSC1TransRate_ACCE "This parameter indicates the transmission rate at which the sending device will transmit the TSC1 message. The engine shall adjust its timeout for TSC1 messages accordingly. Variable TSC1 transmission rates shall only apply to messages sent to the engine.
该参数表示发送设备发送TSC1消息的传输速率。引擎应相应地调整TSC1消息的超时时间。可变的TSC1传输速率仅适用于发送到发动机的消息。";
CM_ SG_ 2348810282 TSC1CtrlPurpose_ACCE "State signal which indicates which control mode the sending device is using to generate the TSC1 command. Note that the modes are not in prioritized order. Not all modes may be relevant for a given device. Some devices may not implement all functions. The TSC1 control purpose shall only apply to messages sent to the engine.
指示发送设备使用哪种控制模式来生成TSC1命令。注意，这些模式并不是按照优先顺序排列的。并非所有模式都适用于特定设备。有些设备可能不能实现所有的功能。TSC1的控制用途仅适用于发送给发动机的消息。";
CM_ SG_ 2348810282 EngReqTorqueHighResolution_ACCE "This parameter displays an additional torque in percent of the reference engine torque.
发动机扭矩请求的小数部分";
CM_ SG_ 2348810282 MessageCounter_ACCE "The message counter is used to detect situations where the transmitting ECU malfunction repeats the same frame all the time.The receiver of the formation may use the counter parameter to detect this situation. The transmitting device will increase themessage counter in every cycle. The message counter will count from 0 to 7 and then wrap. The values 0x8 thru 0xE are SAEreserved and should be ignored by the receiver.Value 0xF (all bits set to 1) will indicate that the message counter is not available.For co";
CM_ SG_ 2348810282 MessageChecksum_ACCE "The message checksum is used to verify the signal path from the transmitting device to the receiving device.The message checksum is calculated using the first 7 data bytes, the message counter and the bytes of the messageidentifier. It is calculated as follows:Checksum = (Byte1 + Byte2 + Byte3 + Byte4 + Byte5 + Byte6 + Byte7 + message counter & 0x0F + message ID low byte +message ID mid low byte + message ID mid high byte + message ID high byte)Message Checksum = (((Checksum >> 6) & 0x03) + (Checksum >>3)";
CM_ SG_ 2349075360 ExternalTargetDecelReq "用于表示外部的目标减速度需求。";
CM_ SG_ 2349075360 EBIMode "表示EBI控制模式。";
CM_ SG_ 2349075360 ExternalBrakeReqPriority "外部制动请求优先级";
CM_ SG_ 2349075360 ExternalBrakeReqCtrlMode "外部制动请求控制模式";
CM_ SG_ 2349075360 RollingCounter "报文计数器用于检测由于报文发送者故障导致重复发生同一帧报文。报文接收者可以使用报文计数器检测到这种情况。报文发送者在每个报文发送周期令报文计数器增1，报文计时器从0开始计数直到15，然后再从0开始计数。";
CM_ SG_ 2349075360 CheckSum "报文校验和用于验证从发送设备到接收设备的信号传输路径。校验和是下述数据的和：报文ID由高字节至低字节的和、数据区前7个字节以及报文计数器。校验和计算公式如下：
校验和 = (字节1 + 字节2 + 字节3 + 字节4 + 字节5 +字节6 + 字节7 + 报文计数器 & 0x0F + 报文ID低字节+ 报文ID中低字节 + 报文ID中高字节 + 报文ID高字节)
校验和 = ((校验和 >> 4) + 校验和) & 0x0F";
CM_ SG_ 2348875814 TransmissionGearReq "表示驾驶员、ADV、ABS或发动机请求档位。(MT车型档位显示，AMT车型取消该信号）
负数表示倒档, 正值表示前进档, 0表示空挡。
特殊取值定义如下:
0xFD (253 dec) = 保持当前档位(D(手动))
0xFC (252 dec) = 前进档位(D(自动))
0xF0 (240 dec)- 0xFB (251 dec) = 保留
0xE0 (224 dec) = 档位不确定或者无按键按下
0xDF (223 dec) = 倒档档位选择(倒档)
0xE1 - 0xEF(225 dec - 239 dec) = 保留
0xDE - 0xBE (222 dec - 190 dec) = 保留
0x3C - 0x00 (60 dec - 0 dec) = 保留
注:0x7D(125 dec)=空挡";
CM_ BO_ 2566864170 "Electronic Parking Brake 2";
CM_ SG_ 2566864170 ExtpressuredemandforEPB "External pressure demand for Electronic Parking Brake
FE: Error
FF: Not available";
CM_ SG_ 2566864170 ExtinhibitionRQforPBrelease "External inhibition request for Parking Brake release外部抑制驻车制动释放请求";
CM_ SG_ 2566864170 ExtinhibitionRQforPBapplication "External inhibition request for Parking Brake application";
CM_ SG_ 2566864170 ExtapplicationRQforEPB "External application request for Electronic Parking Brake";
CM_ SG_ 2566864170 ExtreleaseRQforEPB "External release request for Electronic Parking Brake外部释放电子驻车制动器请求";
CM_ SG_ 2566864170 AutonomousDriving "智驾模式";
CM_ SG_ 2566864170 MessageCounter "The message counter is to verify the signal path from the demanding device to the brake controller on electronic brake systems.";
CM_ SG_ 2566864170 MessageChecksum "Checksum=(Byte1+Byte2+Byte3+Byte4+Byte5+Byte6+Byte7+message counter & 0x0F +
message ID low byte + message ID mid low byte + message ID mid high byte + message ID high byte)
Message Checksum =((Checksum>>4)+Checksum)& 0x0F";
CM_ SG_ 2566857510 ADUStatus "表示ADU)实际工作状态。接口说明：VCU接收控制模式为沿变模式， ADU控制需按照周期性发送，且需发送5个连续的控制模式0，然后发送控制模式1.
备注：如当前不满足ADU控制模式，（VCU自动驾驶相关状态报文中信号AutoToManualTips会说明不满足的条件），在满足条件后，仍然需要发送5个连续的控制模式0，然后发送控制模式1，才能进入无人模式.";
CM_ SG_ 2566857510 BrakeSwtich "表示ADU发送的制动开关信号。";
CM_ SG_ 2566858534 Front_Operator_Wiper_Switch_cmd "该信号表示雨刮开关控制命令，用于ADV控制BCM驱动雨刮。";
CM_ SG_ 2566858534 Front_Operator_Washer_Switch_cmd "该信号表示洗涤开关控制命令，用于ADV控制BCM驱动雨刷。";
CM_ SG_ 2566858534 ADV_to_BCM "该信号表示ADV对BCM的请求控制命令。";
CM_ SG_ 2566858534 DriverDoor1UnlockingRequest "该信号表示主驾驶侧车门解闭锁请求，用于ADV控制DCM。";
CM_ SG_ 2566858534 PassengerDoor2UnlockingRequest "该信号表示副驾驶侧车门解闭锁请求，用于ADV控制DCM。";
CM_ SG_ 2566858534 Back_brake_light_cmd "该信号表示后制动开关，用于ADV控制BCM点亮后制动灯。";
CM_ SG_ 2566858534 Horn_cmd "该信号用于控制前后喇叭命令。";
CM_ SG_ 2566779431 VCUMode "表示VCU实际工作模式状态。";
CM_ SG_ 2566779431 ManualBrakeSwitch "表示VCU发送的制动开关信号。注：只有有人踩下才会变化";
CM_ SG_ 2566779431 ManualAccelPedalPosition "表示VCU发送的油门开关信号。注：只有有人踩下才会变化";
CM_ SG_ 2566779431 AutoToManualTips "16个位分别代表不同的条件：
位1：舒适CAN总线关闭；
位2：动力CAN总线关闭；
位3：ADV控制模式报文超时；
位4：ADV扭矩请求报文CS/LC故障；
位5：手刹开关拉下；
位6：挂车手刹开关拉下；
位7：巡航激活；
位8：油门踩下大于一定阈值；
位9：油门踏板故障时；
位10：刹车踏板踩下；
位11：刹车踏板故障时；
位12：智能驾驶功能屏蔽。";
CM_ SG_ 2566769953 FrontOperatorWiperSwitch "State of operation selected by operator switch for the Wiper in front of the operator position. This parameter, 'Front Operator Wiper Switch' should be used for the control information if either of the other wiper switch parameters is 'Not ...";
CM_ SG_ 2566769953 FrontOperatorWasherSwitch "State of operation selected by operator switch for the washer in front of the operator position. This parameter, 'Front Operator Washer Switch' should be used for the control information if either of the other washer switch parameters  is 'Not ...";
CM_ BO_ 2566849057 "Switch_command";
CM_ SG_ 2566849057 IGOFFPositionLightAlert "Signal which indicates position light alert status. When alert condition is meeted, 0x1 is sent.";
CM_ SG_ 2566849057 LDWSwitchStatus "Signal which indicates LDW Switch status. It is the nonlocking switch, the signal value should be 1during the switch be pressed.";
CM_ SG_ 2566849057 FCWSwitchStatus "Signal which indicates FCW Switch status. It is the nonlocking switch, the signal value should be 1during the switch be pressed.";
CM_ SG_ 2566849057 ReverseGearSwitch "Indicates the status of reverse gear switch.";
CM_ SG_ 2566849057 RearWorkLampSwitch "Indicates the status of rear work lamp switch.";
CM_ SG_ 2566849057 SleepAreaLightSwitch "Switch signal which indicates the status of “sleep area light“. It is the nonlocking switch, the signalvalue should be 1 during the switch be pressed.";
CM_ SG_ 2566849057 IndoorLightSwitch "Switch signal which indicates the status of “indoor light“. It is the nonlocking switch, the signalvalue should be 1 during the switch be pressed.";
CM_ SG_ 2566849057 HornSwitch "Switch signal which indicates the status of menu “horn“. It is the nonlocking switch, the signal valueshould be 1 during the switch be pressed.";
CM_ SG_ 2566849057 HornSelectionSwitch "indicate the selected position of the horn selection switch.";
CM_ SG_ 2566849057 CabDoorWarningOFFSwitch "indicate the cab door warning off switch.";
CM_ SG_ 2566849057 AutoLightControlSwitch "indicate the auto light control switch.";
CM_ SG_ 2566848801 IGNSts "表示车辆点火开关所处的位置";
CM_ SG_ 2566848801 DriverSeatBeltNotFastenedAlert "Indicates whether the driver's side safety belt is not fastened to alarm";
CM_ SG_ 2566848801 PassengerSeatBeltNotFastenedAler "Indicates whether the Passenger side safety belt is not fastened to alarm";
CM_ SG_ 2566849575 HCUSts "表示整车控制器系统工作状态：00：正常；01：报警，整车控制器自检输出一般故障；10：故障整车控制器自检输出严重故障";
CM_ SG_ 2566849575 ReadyToDriveSts "表示整车运行准备就绪状态。00：未就绪；01：附件工作就绪；10：电机工作就绪；11：整车可以驱动。";
CM_ SG_ 2566849575 PermittingCharging "Indicates whether charging is allowed.：";
CM_ SG_ 2566849575 EnduranceMileage "Indicates the mileage, used for the display of the instrument.The actual physical value range is 0km-500km。";
CM_ SG_ 2566849575 SleepCommand "Indicates the sleep command sent by HCU. After receiving it, the receiving node realizes the sleepwake function according to the network sleep wake strategy：";
CM_ SG_ 2566849575 HighVoltageSystemFailureStatus "Indicates High Voltage System Failure Status
Level 1 failure: alarm；
Level 2 failure: limit；
Level 2 failure: Shut Down";
CM_ SG_ 2566862323 PowerBatteryVoltage "Represents the power battery voltage.The actual physical value ranges from 0V to 1000V.";
CM_ SG_ 2566862323 PowerBatteryCurrent "Represents power battery current, negative value represents charge, positive value represents";
CM_ SG_ 2566862323 PowerBatterySOC "Represents the remaining charge of the power battery.";
CM_ SG_ 2566862323 PowerBatterySystemStatus "Represents the current working status of the power battery system.The first alarm is a general fault;The secondary alarm is a serious fault; (limited power)Three-level alarm for emergency failure; (electricity)";
CM_ SG_ 2566862323 PowerBatteryChargingRequest "Indicates whether there is a charge request.000：No charge request before charge ready001：When the charging is ready, send the charging request010：Request charging stop in case of recoverable fault (reservation)011：Unrecoverable fault occurs, request for charging (reservation)";
CM_ SG_ 2566862323 PowerBatteryChargingStatus "Represents the current charging state of the power battery.";
CM_ SG_ 2566862323 PowerBatteryheatingStatus "Indicates the heating state of the power battery";
CM_ SG_ 2566863603 BMSMainnegativeCoilDriveState "BMS primary negative coil drive state";
CM_ SG_ 2566863603 PowerBatterySOH "Represents the battery health status, and the value range is 0-100%.";
CM_ SG_ 2566863603 MainNegativeRelayDisconnectReque "Represents that BMS sends the main-negative relay disconnect request to HCU:
When the HCU has no response, the BMS will actively disconnect the main-negative relay after 30s";
CM_ SG_ 2566863603 MainNegativeRelayStatus "Represents the state of the main-negative relay";
CM_ SG_ 2566863603 PositiveRelayControlCommand "Indicates the Battery Pack Heating Positive Relay Control Command Signal";
CM_ SG_ 2566863603 NegativeRelayControlCommand "Indicates the Battery Pack Heating Negative Relay Control Command Signal";
CM_ SG_ 2566863603 ChargingPlugConnectionStatus "Indicates the connection status of the charging plug.If the dual gun is charged, the signal indicates cc2-1.";
CM_ SG_ 2566863603 ChargingPlugConnectionStatus2 "Represents the connection status of charging plug 2. The signal can only be obtained when the dualgun is charged (cc2-2)";
CM_ SG_ 2566863603 PositiveRelayStatus "Represents the state of charging positive relay.";
CM_ SG_ 2566863603 NegativeRelayStatus "Represents the state of charging negative relay.";
CM_ BO_ 2566840343 "Vehicle Distance";
CM_ SG_ 2566840343 TripDistance "Distance traveled during all or part of a journey.

NOTE See SPN 918 for alternate resolution.";
CM_ SG_ 2566840343 TotalVehicleDistance "Accumulated distance traveled by vehicle during its operation.

NOTE See SPN 917 for alternate resolution.";
CM_ SG_ 2566834721 BCM_AmberWarningLightSts "琥珀色警示灯状态
当检测到车辆系统存在非关键性故障时，需要点亮琥珀色报警灯。这时，并不要求立即停车处理";
CM_ SG_ 2566834721 BCM_RedStopLightSts "红色停止灯状态
如果检测到的危险性故障，会设置红色报警状态。这时，车辆必须停止。";
CM_ SG_ 2566834721 BCM_SAELamp_Reserved "SAE保留分配灯状态";
CM_ SG_ 2566834721 BCM_SPN_LSB "SPN， 8个最低有效位
（第8位是最高有效位）";
CM_ SG_ 2566834721 BCM_SPN_SecondByte "SPN， SPN第二字节
（第8位是最高有效位）";
CM_ SG_ 2566834721 BCM_FMI "FMI用于定义对SPN标识的子系统检测到的故障的类型";
CM_ SG_ 2566834721 BCM_SPN_MSB "SPN， 3个最高有效位
（第8位是最高有效位）";
CM_ SG_ 2566834721 BCM_OC "标识该故障由当前故障转变为历史故障的次数，如果故障发生次数不可知则全置位1";
CM_ SG_ 2566834721 BCM_CM "SPN转换方式,始终是0";
CM_ BO_ 2348814378 "See TSC1_ACCE";
CM_ BO_ 2566841127 "Vehicle Distance";
CM_ SG_ 2566841127 EngineSpeedAtIdle_Point1 "Engine Speed At Idle, Point 1";
CM_ SG_ 2566841127 Reference_engine_torque_Drive "Reference engine torque_Drive";
CM_ SG_ 2566841127 SupportVariableRateTSC1 "Support Variable Rate TSC1 Message";
CM_ SG_ 2566799393 RunningLightSts "行车灯状态";
CM_ SG_ 2566799393 LowBeamSts "近光灯的状态";
CM_ SG_ 2566799393 HighBeamSts "远光灯的状态";
CM_ SG_ 2566799393 RightLampSts "右转向灯状态";
CM_ SG_ 2566799393 LeftLampSts "左转向灯的状态";
CM_ SG_ 2566799393 FrontFogLampSts "前雾灯的状态";
CM_ SG_ 2566799393 RearFogLampSts "后雾灯的状态";
CM_ SG_ 2566799393 ReverseLampSts "倒车灯的状态";
CM_ SG_ 2566799393 PostionLampSts "位置灯的状态";
CM_ SG_ 2566860065 BCMRespSts "表示BCM对ADV的响应状态";
CM_ SG_ 2566860065 BrakeLampSts "表示制动灯的实际状态。用于表示园区洗扫车的制动灯状态";
CM_ SG_ 2566860065 HornContrlSts "表示前后喇叭的实际控制状态。园区洗扫车只有前喇叭";
CM_ SG_ 2566834931 BMS_GuardLampSts "保护灯状态
车辆系统出现问题，极可能电子器件发生故障，一般为临时超过阈值的故障，对应整车一级故障";
CM_ SG_ 2566834931 BMS_AmberWarningLightSts "琥珀色警示灯状态
车辆发生一般故障，不必立刻停车检查，对应整车二级故障";
CM_ SG_ 2566834931 BMS_RedStopLightSts "红色停止灯状态
车辆发生严重故障，必须立刻停车检查，对应整车三级故障";
CM_ SG_ 2566834931 BMS_FaultIndicatorSts "故障指示灯状态
与发动机排放相关";
CM_ SG_ 2566834931 BMS_GuardLampBlinking "保护灯闪烁方式";
CM_ SG_ 2566834931 BMS_AmberWarningLightBlinking "琥珀色警示灯闪烁方式";
CM_ SG_ 2566834931 BMS_RedStopLightBlingking "红色停止灯闪烁方式";
CM_ SG_ 2566834931 BMS_FaultIndicatorBlinking "故障指示灯闪烁方式";
CM_ SG_ 2566834931 BMS_SPN_LSB "故障SPN的8个最低有效位";
CM_ SG_ 2566834931 BMS_SPN_SecondByte "SPN， SPN第二字节
（第8位是最高有效位）";
CM_ SG_ 2566834931 BMS_FMI "故障模式标识符,FMI（第5位是最高有效位）";
CM_ SG_ 2566834931 BMS_SPN_MSB "SPN， 3个最高有效位
（第8位是最高有效位）";
CM_ SG_ 2566834931 BMS_OC "发生频次，范围1～126，如果发生故障此数据就加一，故障消除后数据保存在NVM中，再次发生故障时，此数据再加一，数据最大为126，并保持126不变。";
CM_ SG_ 2566834931 BMS_CM "固定为0，SPN为intel格式";
CM_ SG_ 2566834784 PTU_GuardLampSts "保护灯状态
车辆系统出现问题，极可能电子器件发生故障，一般为临时超过阈值的故障，对应整车一级故障";
CM_ SG_ 2566834784 PTU_AmberWarningLightSts "琥珀色警示灯状态
车辆发生一般故障，不必立刻停车检查，对应整车二级故障";
CM_ SG_ 2566834784 PTU_RedStopLightSts "红色停止灯状态
车辆发生严重故障，必须立刻停车检查，对应整车三级故障";
CM_ SG_ 2566834784 PTU_FaultIndicatorSts "故障指示灯状态
与发动机排放相关";
CM_ SG_ 2566834784 PTU_GuardLampBlinking "保护灯闪烁方式";
CM_ SG_ 2566834784 PTU_AmberWarningLightBlinking "琥珀色警示灯闪烁方式";
CM_ SG_ 2566834784 PTU_RedStopLightBlingking "红色停止灯闪烁方式";
CM_ SG_ 2566834784 PTU_FaultIndicatorBlinking "故障指示灯闪烁方式";
CM_ SG_ 2566834784 PTU_SPN_LSB "故障SPN的8个最低有效位";
CM_ SG_ 2566834784 PTU_SPN_SecondByte "SPN， SPN第二字节
（第8位是最高有效位）";
CM_ SG_ 2566834784 PTU_FMI "故障模式标识符,FMI（第5位是最高有效位）";
CM_ SG_ 2566834784 PTU_SPN_MSB "SPN， 3个最高有效位
（第8位是最高有效位）";
CM_ SG_ 2566834784 PTU_OC "发生频次，范围1～126，如果发生故障此数据就加一，故障消除后数据保存在NVM中，再次发生故障时，此数据再加一，数据最大为126，并保持126不变。";
CM_ SG_ 2566834784 PTU_CM "固定为0，SPN为intel格式";
CM_ SG_ 2566834741 DCDC2_GuardLampSts "保护灯状态
车辆系统出现问题，极可能电子器件发生故障，一般为临时超过阈值的故障，对应整车一级故障";
CM_ SG_ 2566834741 DCDC2_AmberWarningLightSts "琥珀色警示灯状态
车辆发生一般故障，不必立刻停车检查，对应整车二级故障";
CM_ SG_ 2566834741 DCDC2_RedStopLightSts "红色停止灯状态
车辆发生严重故障，必须立刻停车检查，对应整车三级故障";
CM_ SG_ 2566834741 DCDC2_FaultIndicatorSts "故障指示灯状态
与发动机排放相关";
CM_ SG_ 2566834741 DCDC2_GuardLampBlinking "保护灯闪烁方式";
CM_ SG_ 2566834741 DCDC2_AmberWarningLightBlinking "琥珀色警示灯闪烁方式";
CM_ SG_ 2566834741 DCDC2_RedStopLightBlingking "红色停止灯闪烁方式";
CM_ SG_ 2566834741 DCDC2_FaultIndicatorBlinking "故障指示灯闪烁方式";
CM_ SG_ 2566834741 DCDC2_SPN_LSB "故障SPN的8个最低有效位";
CM_ SG_ 2566834741 DCDC2_SPN_SecondByte "SPN， SPN第二字节
（第8位是最高有效位）";
CM_ SG_ 2566834741 DCDC2_FMI "故障模式标识符,FMI（第5位是最高有效位）";
CM_ SG_ 2566834741 DCDC2_SPN_MSB "SPN， 3个最高有效位
（第8位是最高有效位）";
CM_ SG_ 2566834741 DCDC2_OC "发生频次，范围1～126，如果发生故障此数据就加一，故障消除后数据保存在NVM中，再次发生故障时，此数据再加一，数据最大为126，并保持126不变。";
CM_ SG_ 2566834741 DCDC2_CM "固定为0，SPN为intel格式";
CM_ SG_ 2566834736 APCU_GuardLampSts "保护灯状态
车辆系统出现问题，极可能电子器件发生故障，一般为临时超过阈值的故障，对应整车一级故障";
CM_ SG_ 2566834736 APCU_AmberWarningLightSts "琥珀色警示灯状态
车辆发生一般故障，不必立刻停车检查，对应整车二级故障";
CM_ SG_ 2566834736 APCU_RedStopLightSts "红色停止灯状态
车辆发生严重故障，必须立刻停车检查，对应整车三级故障";
CM_ SG_ 2566834736 APCU_FaultIndicatorSts "故障指示灯状态
与发动机排放相关";
CM_ SG_ 2566834736 APCU_GuardLampBlinking "保护灯闪烁方式";
CM_ SG_ 2566834736 APCU_AmberWarningLightBlinking "琥珀色警示灯闪烁方式";
CM_ SG_ 2566834736 APCU_RedStopLightBlingking "红色停止灯闪烁方式";
CM_ SG_ 2566834736 APCU_FaultIndicatorBlinking "故障指示灯闪烁方式";
CM_ SG_ 2566834736 APCU_SPN_LSB "故障SPN的8个最低有效位";
CM_ SG_ 2566834736 APCU_SPN_SecondByte "SPN， SPN第二字节
（第8位是最高有效位）";
CM_ SG_ 2566834736 APCU_FMI "故障模式标识符,FMI（第5位是最高有效位）";
CM_ SG_ 2566834736 APCU_SPN_MSB "SPN， 3个最高有效位
（第8位是最高有效位）";
CM_ SG_ 2566834736 APCU_OC "发生频次，范围1～126，如果发生故障此数据就加一，故障消除后数据保存在NVM中，再次发生故障时，此数据再加一，数据最大为126，并保持126不变。";
CM_ SG_ 2566834736 APCU_CM "固定为0，SPN为intel格式";
CM_ BO_ 2632777552 "refer to 《SAE J1939-21 SURFACE VEHICLE RECOMMENDED PRACTICE：Data Link Layer》";
CM_ BO_ 2632712016 "refer to 《SAE J1939-21 SURFACE VEHICLE RECOMMENDED PRACTICE：Data Link Layer》";
CM_ BO_ 2632777483 "refer to 《SAE J1939-21 SURFACE VEHICLE RECOMMENDED PRACTICE：Data Link Layer》";
CM_ BO_ 2632711947 "refer to 《SAE J1939-21 SURFACE VEHICLE RECOMMENDED PRACTICE：Data Link Layer》";
CM_ BO_ 2632777491 "refer to 《SAE J1939-21 SURFACE VEHICLE RECOMMENDED PRACTICE：Data Link Layer》";
CM_ BO_ 2632711955 "refer to 《SAE J1939-21 SURFACE VEHICLE RECOMMENDED PRACTICE：Data Link Layer》";
CM_ BO_ 2632777505 "refer to 《SAE J1939-21 SURFACE VEHICLE RECOMMENDED PRACTICE：Data Link Layer》";
CM_ BO_ 2632711969 "refer to 《SAE J1939-21 SURFACE VEHICLE RECOMMENDED PRACTICE：Data Link Layer》";
CM_ BO_ 2632777523 "refer to 《SAE J1939-21 SURFACE VEHICLE RECOMMENDED PRACTICE：Data Link Layer》";
CM_ BO_ 2632711987 "refer to 《SAE J1939-21 SURFACE VEHICLE RECOMMENDED PRACTICE：Data Link Layer》";
CM_ BO_ 2632777715 "refer to 《SAE J1939-21 SURFACE VEHICLE RECOMMENDED PRACTICE：Data Link Layer》";
CM_ BO_ 2632712179 "refer to 《SAE J1939-21 SURFACE VEHICLE RECOMMENDED PRACTICE：Data Link Layer》";
CM_ BO_ 2632777511 "refer to 《SAE J1939-21 SURFACE VEHICLE RECOMMENDED PRACTICE：Data Link Layer》";
CM_ BO_ 2632711975 "refer to 《SAE J1939-21 SURFACE VEHICLE RECOMMENDED PRACTICE：Data Link Layer》";
CM_ BO_ 2632777568 "refer to 《SAE J1939-21 SURFACE VEHICLE RECOMMENDED PRACTICE：Data Link Layer》";
CM_ BO_ 2632712032 "refer to 《SAE J1939-21 SURFACE VEHICLE RECOMMENDED PRACTICE：Data Link Layer》";
CM_ BO_ 2632777525 "refer to 《SAE J1939-21 SURFACE VEHICLE RECOMMENDED PRACTICE：Data Link Layer》";
CM_ BO_ 2632711989 "refer to 《SAE J1939-21 SURFACE VEHICLE RECOMMENDED PRACTICE：Data Link Layer》";
CM_ BO_ 2632777520 "refer to 《SAE J1939-21 SURFACE VEHICLE RECOMMENDED PRACTICE：Data Link Layer》";
CM_ BO_ 2632711984 "refer to 《SAE J1939-21 SURFACE VEHICLE RECOMMENDED PRACTICE：Data Link Layer》";
BA_DEF_ SG_  "GenSigSendType" ENUM  "Cycle","OnChange","OnWrite","IfActive","OnChangeWithRepetition","OnWriteWithRepetition","IfActiveWithRepetition","NoSigSendType","OnChangeAndIfActive","OnChangeAndIfActiveWithRepetition","CA","CE","Event";
BA_DEF_ SG_  "SPN" INT 0 0;
BA_DEF_ SG_  "GenSigInactiveValue" HEX 0 0;
BA_DEF_ SG_  "GenSigStartValue" HEX 0 0;
BA_DEF_  "BusType" STRING ;
BA_DEF_  "Baudrate" INT 0 1000000;
BA_DEF_  "VersionYear" INT 2010 2999;
BA_DEF_  "NmMessageCount" INT 0 255;
BA_DEF_  "ProtocolType" STRING ;
BA_DEF_  "DBName" STRING ;
BA_DEF_  "NmType" STRING ;
BA_DEF_ BU_  "NmCAN" INT 1 2;
BA_DEF_ BU_  "NodeLayerModules" STRING ;
BA_DEF_ BU_  "ILUsed" ENUM  "No","Yes";
BA_DEF_ BO_  "GenMsgNrOfRepetition" INT 0 0;
BA_DEF_ BO_  "GenMsgStartDelayTime" INT 0 0;
BA_DEF_ BO_  "VFrameFormat" ENUM  "StandardCAN","ExtendedCAN","StandardCAN_FD","ExtendedCAN_FD","StandardCAN_FD","ExtendedCAN_FD","J1939PG";
BA_DEF_ BO_  "GenMsgCycleTime" INT 0 0;
BA_DEF_ BO_  "GenMsgDelayTime" INT 0 0;
BA_DEF_ BO_  "DiagRequest" ENUM  "No","Yes";
BA_DEF_ BO_  "CANFD_BRS" ENUM  "0","1";
BA_DEF_ BO_  "GenMsgCycleTimeFast" INT 0 0;
BA_DEF_ BO_  "GenMsgILSupport" ENUM  "No","Yes";
BA_DEF_ BO_  "GenMsgSendType" ENUM  "Cycle","NoMsgSendType","IfActive","Event","CA","CE";
BA_DEF_ SG_  "SystemSignalLongSymbol" STRING ;
BA_DEF_DEF_  "GenSigSendType" "Cycle";
BA_DEF_DEF_  "SPN" 0;
BA_DEF_DEF_  "GenSigInactiveValue" 0;
BA_DEF_DEF_  "GenSigStartValue" 0;
BA_DEF_DEF_  "BusType" "CAN";
BA_DEF_DEF_  "Baudrate" 500000;
BA_DEF_DEF_  "VersionYear" 2019;
BA_DEF_DEF_  "NmMessageCount" 128;
BA_DEF_DEF_  "ProtocolType" "";
BA_DEF_DEF_  "DBName" "";
BA_DEF_DEF_  "NmType" "OSEK";
BA_DEF_DEF_  "NmCAN" 2;
BA_DEF_DEF_  "NodeLayerModules" "OSEKNM01.dll,CANoeILNLVector.dll";
BA_DEF_DEF_  "ILUsed" "Yes";
BA_DEF_DEF_  "GenMsgNrOfRepetition" 0;
BA_DEF_DEF_  "GenMsgStartDelayTime" 0;
BA_DEF_DEF_  "VFrameFormat" "StandardCAN";
BA_DEF_DEF_  "GenMsgCycleTime" 100;
BA_DEF_DEF_  "GenMsgDelayTime" 0;
BA_DEF_DEF_  "DiagRequest" "No";
BA_DEF_DEF_  "CANFD_BRS" "1";
BA_DEF_DEF_  "GenMsgCycleTimeFast" 0;
BA_DEF_DEF_  "GenMsgILSupport" "Yes";
BA_DEF_DEF_  "GenMsgSendType" "Cycle";
BA_DEF_DEF_  "SystemSignalLongSymbol" "";
BA_ "ProtocolType" "J1939";
BA_ "DBName" "J6F_ADCAN";
BA_ "VFrameFormat" BO_ 2566844672 6;
BA_ "VFrameFormat" BO_ 2565866755 6;
BA_ "GenMsgCycleTime" BO_ 2566834768 1000;
BA_ "GenMsgCycleTimeFast" BO_ 2566834768 1000;
BA_ "DiagRequest" BO_ 2566834768 1;
BA_ "VFrameFormat" BO_ 2566834768 6;
BA_ "VFrameFormat" BO_ 2566863952 6;
BA_ "GenMsgCycleTime" BO_ 2566834699 1000;
BA_ "GenMsgCycleTimeFast" BO_ 2566834699 1000;
BA_ "DiagRequest" BO_ 2566834699 1;
BA_ "VFrameFormat" BO_ 2566834699 6;
BA_ "VFrameFormat" BO_ 2565865739 6;
BA_ "GenMsgCycleTime" BO_ 2566831883 50;
BA_ "VFrameFormat" BO_ 2566831883 6;
BA_ "VFrameFormat" BO_ 2566767627 6;
BA_ "GenMsgCycleTime" BO_ 2565868307 20;
BA_ "VFrameFormat" BO_ 2565868307 6;
BA_ "GenMsgSendType" BO_ 2566811659 3;
BA_ "VFrameFormat" BO_ 2566811659 6;
BA_ "GenMsgCycleTime" BO_ 2565867787 10;
BA_ "VFrameFormat" BO_ 2565867787 6;
BA_ "GenMsgDelayTime" BO_ 2365473062 100;
BA_ "VFrameFormat" BO_ 2365473062 3;
BA_ "GenMsgCycleTime" BO_ 2365473057 35;
BA_ "GenMsgDelayTime" BO_ 2365473057 100;
BA_ "VFrameFormat" BO_ 2365473057 6;
BA_ "VFrameFormat" BO_ 2566759713 3;
BA_ "GenMsgCycleTime" BO_ 2365578991 10;
BA_ "VFrameFormat" BO_ 2365578991 6;
BA_ "GenMsgCycleTime" BO_ 2566834707 1000;
BA_ "GenMsgCycleTimeFast" BO_ 2566834707 1000;
BA_ "DiagRequest" BO_ 2566834707 1;
BA_ "VFrameFormat" BO_ 2566834707 6;
BA_ "GenMsgCycleTime" BO_ 2566910227 10;
BA_ "VFrameFormat" BO_ 2566910227 6;
BA_ "GenMsgCycleTime" BO_ 2566909971 10;
BA_ "VFrameFormat" BO_ 2566909971 6;
BA_ "GenMsgCycleTime" BO_ 2566845491 1000;
BA_ "VFrameFormat" BO_ 2566845491 6;
BA_ "GenMsgCycleTime" BO_ 2566668851 1000;
BA_ "VFrameFormat" BO_ 2566668851 6;
BA_ "GenMsgCycleTime" BO_ 2566897971 1000;
BA_ "VFrameFormat" BO_ 2566897971 6;
BA_ "GenMsgCycleTime" BO_ 2566834739 1000;
BA_ "GenMsgCycleTimeFast" BO_ 2566834739 1000;
BA_ "DiagRequest" BO_ 2566834739 1;
BA_ "VFrameFormat" BO_ 2566834739 6;
BA_ "GenMsgCycleTime" BO_ 2364539648 50;
BA_ "VFrameFormat" BO_ 2364539648 6;
BA_ "GenMsgCycleTime" BO_ 2348810282 10;
BA_ "VFrameFormat" BO_ 2348810282 6;
BA_ "GenMsgCycleTime" BO_ 2349075360 20;
BA_ "VFrameFormat" BO_ 2349075360 6;
BA_ "GenMsgCycleTime" BO_ 2348875814 50;
BA_ "VFrameFormat" BO_ 2348875814 6;
BA_ "VFrameFormat" BO_ 2566864170 6;
BA_ "VFrameFormat" BO_ 2566857510 6;
BA_ "GenMsgCycleTime" BO_ 2566858534 20;
BA_ "VFrameFormat" BO_ 2566858534 6;
BA_ "VFrameFormat" BO_ 2566779431 6;
BA_ "GenMsgCycleTime" BO_ 2566769953 200;
BA_ "VFrameFormat" BO_ 2566769953 6;
BA_ "VFrameFormat" BO_ 2566849057 6;
BA_ "VFrameFormat" BO_ 2566848801 6;
BA_ "VFrameFormat" BO_ 2566849575 6;
BA_ "VFrameFormat" BO_ 2566862323 6;
BA_ "GenMsgCycleTime" BO_ 2566863603 20;
BA_ "VFrameFormat" BO_ 2566863603 6;
BA_ "VFrameFormat" BO_ 2566840343 6;
BA_ "GenMsgCycleTime" BO_ 2566834721 1000;
BA_ "DiagRequest" BO_ 2566834721 1;
BA_ "VFrameFormat" BO_ 2566834721 6;
BA_ "GenMsgCycleTime" BO_ 2348814378 50;
BA_ "VFrameFormat" BO_ 2348814378 6;
BA_ "GenMsgCycleTime" BO_ 2566841127 5000;
BA_ "VFrameFormat" BO_ 2566841127 6;
BA_ "GenMsgCycleTime" BO_ 2566894099 20;
BA_ "VFrameFormat" BO_ 2566894099 6;
BA_ "GenMsgCycleTime" BO_ 2566893862 20;
BA_ "VFrameFormat" BO_ 2566893862 3;
BA_ "VFrameFormat" BO_ 2566799393 6;
BA_ "VFrameFormat" BO_ 2566860065 6;
BA_ "GenMsgCycleTime" BO_ 2566834931 1000;
BA_ "DiagRequest" BO_ 2566834931 1;
BA_ "VFrameFormat" BO_ 2566834931 6;
BA_ "GenMsgCycleTime" BO_ 2566834784 1000;
BA_ "DiagRequest" BO_ 2566834784 1;
BA_ "VFrameFormat" BO_ 2566834784 6;
BA_ "GenMsgCycleTime" BO_ 2566834741 1000;
BA_ "DiagRequest" BO_ 2566834741 1;
BA_ "VFrameFormat" BO_ 2566834741 6;
BA_ "GenMsgCycleTime" BO_ 2566834736 1000;
BA_ "DiagRequest" BO_ 2566834736 1;
BA_ "VFrameFormat" BO_ 2566834736 6;
BA_ "GenMsgCycleTime" BO_ 2632777552 0;
BA_ "GenMsgSendType" BO_ 2632777552 1;
BA_ "VFrameFormat" BO_ 2632777552 6;
BA_ "GenMsgCycleTime" BO_ 2632712016 0;
BA_ "GenMsgSendType" BO_ 2632712016 1;
BA_ "VFrameFormat" BO_ 2632712016 6;
BA_ "GenMsgCycleTime" BO_ 2632777483 0;
BA_ "GenMsgSendType" BO_ 2632777483 1;
BA_ "VFrameFormat" BO_ 2632777483 6;
BA_ "GenMsgCycleTime" BO_ 2632711947 0;
BA_ "GenMsgSendType" BO_ 2632711947 1;
BA_ "VFrameFormat" BO_ 2632711947 6;
BA_ "GenMsgCycleTime" BO_ 2632777491 0;
BA_ "GenMsgSendType" BO_ 2632777491 1;
BA_ "VFrameFormat" BO_ 2632777491 6;
BA_ "GenMsgCycleTime" BO_ 2632711955 0;
BA_ "GenMsgSendType" BO_ 2632711955 1;
BA_ "VFrameFormat" BO_ 2632711955 6;
BA_ "GenMsgCycleTime" BO_ 2632777505 0;
BA_ "GenMsgSendType" BO_ 2632777505 1;
BA_ "VFrameFormat" BO_ 2632777505 6;
BA_ "GenMsgCycleTime" BO_ 2632711969 0;
BA_ "GenMsgSendType" BO_ 2632711969 1;
BA_ "VFrameFormat" BO_ 2632711969 6;
BA_ "GenMsgCycleTime" BO_ 2632777523 0;
BA_ "GenMsgSendType" BO_ 2632777523 1;
BA_ "VFrameFormat" BO_ 2632777523 6;
BA_ "GenMsgCycleTime" BO_ 2632711987 0;
BA_ "GenMsgSendType" BO_ 2632711987 1;
BA_ "VFrameFormat" BO_ 2632711987 6;
BA_ "GenMsgCycleTime" BO_ 2632777715 0;
BA_ "GenMsgSendType" BO_ 2632777715 1;
BA_ "VFrameFormat" BO_ 2632777715 6;
BA_ "GenMsgCycleTime" BO_ 2632712179 0;
BA_ "GenMsgSendType" BO_ 2632712179 1;
BA_ "VFrameFormat" BO_ 2632712179 6;
BA_ "GenMsgCycleTime" BO_ 2632777511 0;
BA_ "GenMsgSendType" BO_ 2632777511 1;
BA_ "VFrameFormat" BO_ 2632777511 6;
BA_ "GenMsgCycleTime" BO_ 2632711975 0;
BA_ "GenMsgSendType" BO_ 2632711975 1;
BA_ "VFrameFormat" BO_ 2632711975 6;
BA_ "GenMsgCycleTime" BO_ 2632777568 0;
BA_ "GenMsgSendType" BO_ 2632777568 1;
BA_ "VFrameFormat" BO_ 2632777568 6;
BA_ "GenMsgCycleTime" BO_ 2632712032 0;
BA_ "GenMsgSendType" BO_ 2632712032 1;
BA_ "VFrameFormat" BO_ 2632712032 6;
BA_ "GenMsgCycleTime" BO_ 2632777525 0;
BA_ "GenMsgSendType" BO_ 2632777525 1;
BA_ "VFrameFormat" BO_ 2632777525 6;
BA_ "GenMsgCycleTime" BO_ 2632711989 0;
BA_ "GenMsgSendType" BO_ 2632711989 1;
BA_ "VFrameFormat" BO_ 2632711989 6;
BA_ "GenMsgCycleTime" BO_ 2632777520 0;
BA_ "GenMsgSendType" BO_ 2632777520 1;
BA_ "VFrameFormat" BO_ 2632777520 6;
BA_ "GenMsgCycleTime" BO_ 2632711984 0;
BA_ "GenMsgSendType" BO_ 2632711984 1;
BA_ "VFrameFormat" BO_ 2632711984 6;
BA_ "GenSigStartValue" SG_ 2565866755 SelectedGear 125;
BA_ "GenSigStartValue" SG_ 2565866755 CurrentGear 125;
BA_ "GenSigStartValue" SG_ 2566863952 positionofEPBHCU 125;
BA_ "GenSigStartValue" SG_ 2566831883 Relative_Speed_FrontAxle_LeftWhe 125;
BA_ "SystemSignalLongSymbol" SG_ 2566831883 Relative_Speed_FrontAxle_LeftWhe "Relative_Speed_FrontAxle_LeftWheel";
BA_ "GenSigStartValue" SG_ 2566831883 Relative_Speed_FrontAxle_RightWh 125;
BA_ "SystemSignalLongSymbol" SG_ 2566831883 Relative_Speed_FrontAxle_RightWh "Relative_Speed_FrontAxle_RightWheel";
BA_ "GenSigStartValue" SG_ 2566831883 Relative_Speed_RearAxle1_LeftWhe 125;
BA_ "SystemSignalLongSymbol" SG_ 2566831883 Relative_Speed_RearAxle1_LeftWhe "Relative_Speed_RearAxle1_LeftWheel";
BA_ "GenSigStartValue" SG_ 2566831883 Relative_Speed_RearAxle1_RightWh 125;
BA_ "SystemSignalLongSymbol" SG_ 2566831883 Relative_Speed_RearAxle1_RightWh "Relative_Speed_RearAxle1_RightWheel";
BA_ "GenSigStartValue" SG_ 2566831883 Relative_Speed_RearAxle2_LeftWhe 125;
BA_ "SystemSignalLongSymbol" SG_ 2566831883 Relative_Speed_RearAxle2_LeftWhe "Relative_Speed_RearAxle2_LeftWhee";
BA_ "GenSigStartValue" SG_ 2566831883 Relative_Speed_RearAxle2_RightWh 125;
BA_ "SystemSignalLongSymbol" SG_ 2566831883 Relative_Speed_RearAxle2_RightWh "Relative_Speed_RearAxle2_RightWheel";
BA_ "GenSigStartValue" SG_ 2566767627 XBRAccelerationLimit 125;
BA_ "GenSigSendType" SG_ 2566811659 PoweredVehicleWeight 12;
BA_ "GenSigSendType" SG_ 2566811659 GrossCombinationVehicleWeight 12;
BA_ "GenSigStartValue" SG_ 2565867787 SteerWheelAngle 32128;
BA_ "GenSigStartValue" SG_ 2565867787 SteerWheelTurnCounter 32;
BA_ "GenSigStartValue" SG_ 2565867787 YawRate 32128;
BA_ "GenSigStartValue" SG_ 2565867787 LateralAcceleration 32128;
BA_ "GenSigStartValue" SG_ 2565867787 LongitudinalAcceleration 125;
BA_ "SPN" SG_ 2365473062 RunningLightCmd_1 2403;
BA_ "SPN" SG_ 2365473062 LowBeamHeadLightCmd_1 2349;
BA_ "SPN" SG_ 2365473062 HighBeamHeadLightCmd_1 2347;
BA_ "SPN" SG_ 2365473062 TractorFrontFogLightsCmd_1 2387;
BA_ "SPN" SG_ 2365473062 RightTurnSignalLightsCmd_1 2369;
BA_ "SPN" SG_ 2365473062 LeftTurnSignalLightsCmd_1 2367;
BA_ "SPN" SG_ 2365473062 BackUpLightAndAlarmHornCmd_1 2391;
BA_ "SPN" SG_ 2365473062 RearFogLightCmd_1 2389;
BA_ "SPN" SG_ 2365473057 RunningLightCmd 2403;
BA_ "SPN" SG_ 2365473057 LowBeamHeadLightCmd 2349;
BA_ "SPN" SG_ 2365473057 HighBeamHeadLightCmd 2347;
BA_ "SPN" SG_ 2365473057 TractorFrontFogLightsCmd 2387;
BA_ "SPN" SG_ 2365473057 RightTurnSignalLightsCmd 2369;
BA_ "SPN" SG_ 2365473057 LeftTurnSignalLightsCmd 2367;
BA_ "SPN" SG_ 2365473057 BackUpLightAndAlarmHornCmd 2391;
BA_ "SPN" SG_ 2365473057 CenterStopLightCmd 2375;
BA_ "SPN" SG_ 2365473057 RearFogLightCmd 2389;
BA_ "SPN" SG_ 2566759713 LockStatusofDoor1_Driver 3413;
BA_ "SPN" SG_ 2566759713 OpenStatusofDoor1_Driver 3413;
BA_ "SPN" SG_ 2566759713 LockStatusofDoor2_Passenger 3413;
BA_ "SPN" SG_ 2566759713 OpenStatusofDoor2_Passenger 3416;
BA_ "GenSigStartValue" SG_ 2365578991 MotorSts 15;
BA_ "GenSigStartValue" SG_ 2365578991 HighPrecisionActualMotorTrq 15;
BA_ "GenSigStartValue" SG_ 2365578991 HighPrecisionMaxMotorTrq 15;
BA_ "GenSigStartValue" SG_ 2365578991 MotorTrq 125;
BA_ "GenSigStartValue" SG_ 2365578991 MotorMaxTrq 125;
BA_ "GenSigStartValue" SG_ 2566845491 Tire_Location 255;
BA_ "GenSigStartValue" SG_ 2566845491 Tire_Pressure 255;
BA_ "GenSigStartValue" SG_ 2566845491 Tire_Temperature 65535;
BA_ "GenSigStartValue" SG_ 2566845491 Tire_Status 3;
BA_ "GenSigStartValue" SG_ 2566845491 Extended_Tire_Pressure_Support 3;
BA_ "GenSigStartValue" SG_ 2566845491 Tire_AirLeakage_Rate 65535;
BA_ "GenSigStartValue" SG_ 2566668851 Tire_Location 255;
BA_ "GenSigStartValue" SG_ 2566668851 Tire_PressExtedRage 65535;
BA_ "GenSigStartValue" SG_ 2566668851 RequiredTirePressure 65535;
BA_ "GenSigStartValue" SG_ 2566897971 TireLocation 255;
BA_ "GenSigStartValue" SG_ 2566897971 TireSensorMatchStatus 3;
BA_ "GenSigStartValue" SG_ 2566897971 TireSensorSelfLearningStatus 7;
BA_ "GenSigStartValue" SG_ 2566897971 TireSensorElectricalFault 3;
BA_ "GenSigStartValue" SG_ 2566897971 TireTemperatureThresholdDetectio 2;
BA_ "SystemSignalLongSymbol" SG_ 2566897971 TireTemperatureThresholdDetectio "TireTemperatureThresholdDetection";
BA_ "GenSigStartValue" SG_ 2348810282 TorqReqOrTorqLimitReq_ACCE 125;
BA_ "GenSigStartValue" SG_ 2348810282 TSC1TransRate_ACCE 7;
BA_ "GenSigStartValue" SG_ 2348810282 TSC1CtrlPurpose_ACCE 31;
BA_ "GenSigStartValue" SG_ 2348875814 TransmissionGearReq 125;
BA_ "GenSigInactiveValue" SG_ 2566858534 ADV_to_BCM 15;
BA_ "GenSigStartValue" SG_ 2566858534 Horn_cmd 3;
BA_ "SPN" SG_ 2566769953 FrontOperatorWiperSwitch 2863;
BA_ "GenSigStartValue" SG_ 2566769953 FrontOperatorWiperSwitch 15;
BA_ "SPN" SG_ 2566769953 FrontOperatorWasherSwitch 2866;
BA_ "GenSigStartValue" SG_ 2566769953 FrontOperatorWasherSwitch 7;
BA_ "GenSigStartValue" SG_ 2566848801 IGNSts 7;
BA_ "GenSigStartValue" SG_ 2566848801 DriverSeatBeltNotFastenedAlert 3;
BA_ "GenSigStartValue" SG_ 2566848801 PassengerSeatBeltNotFastenedAler 3;
BA_ "SystemSignalLongSymbol" SG_ 2566848801 PassengerSeatBeltNotFastenedAler "PassengerSeatBeltNotFastenedAlert";
BA_ "GenSigInactiveValue" SG_ 2566862323 PowerBatteryCurrent 32000;
BA_ "GenSigStartValue" SG_ 2566863603 BMSMainnegativeCoilDriveState 3;
BA_ "GenSigStartValue" SG_ 2566863603 PowerBatterySOH 255;
BA_ "GenSigStartValue" SG_ 2566863603 MainNegativeRelayDisconnectReque 3;
BA_ "SystemSignalLongSymbol" SG_ 2566863603 MainNegativeRelayDisconnectReque "MainNegativeRelayDisconnectRequest";
BA_ "GenSigStartValue" SG_ 2566863603 MainNegativeRelayStatus 7;
BA_ "GenSigStartValue" SG_ 2566863603 PositiveRelayControlCommand 3;
BA_ "GenSigStartValue" SG_ 2566863603 NegativeRelayControlCommand 3;
BA_ "GenSigStartValue" SG_ 2566863603 ChargingPlugConnectionStatus 3;
BA_ "GenSigStartValue" SG_ 2566863603 ChargingPlugConnectionStatus2 3;
BA_ "GenSigStartValue" SG_ 2566863603 PositiveRelayStatus 7;
BA_ "GenSigStartValue" SG_ 2566863603 NegativeRelayStatus 7;
BA_ "SPN" SG_ 2566840343 TripDistance 244;
BA_ "SPN" SG_ 2566840343 TotalVehicleDistance 245;
BA_ "GenSigStartValue" SG_ 2566834721 BCM_SAELamp_Reserved 255;
BA_ "GenSigStartValue" SG_ 2348814378 TSC1TransRate_ACCDR 7;
BA_ "GenSigStartValue" SG_ 2348814378 TSC1CtrlPurpose_ACCDR 31;
BA_ "GenSigStartValue" SG_ 2566841127 Reference_engine_torque_Drive 65535;
BA_ "GenSigStartValue" SG_ 2566841127 SupportVariableRateTSC1 255;
BA_ "GenSigStartValue" SG_ 2566894099 Steeringwheel_Angle 15750;
BA_ "GenSigStartValue" SG_ 2566894099 MotorAssist_Torque 32894.7368421053;
BA_ "GenSigStartValue" SG_ 2566894099 HandMomentSignal 128;
BA_ "GenSigStartValue" SG_ 2566893862 TargetSteeringWheelCommand 65535;
BA_ "GenSigStartValue" SG_ 2566893862 OperatingModeInstruction 15;
BA_ "GenSigStartValue" SG_ 2566893862 ADV_status 1;
BA_ "GenSigStartValue" SG_ 2566893862 SteeringAngleCommand 1;
BA_ "GenSigStartValue" SG_ 2566893862 SteeringSuperimposedTorque 255;
BA_ "GenSigStartValue" SG_ 2566893862 SteeringWheelTargetAngular 255;
BA_ "GenSigStartValue" SG_ 2566799393 RunningLightSts 3;
BA_ "GenSigStartValue" SG_ 2566799393 LowBeamSts 3;
BA_ "GenSigStartValue" SG_ 2566799393 HighBeamSts 3;
BA_ "GenSigStartValue" SG_ 2566799393 RightLampSts 3;
BA_ "GenSigStartValue" SG_ 2566799393 LeftLampSts 3;
BA_ "GenSigStartValue" SG_ 2566799393 FrontFogLampSts 3;
BA_ "GenSigStartValue" SG_ 2566799393 RearFogLampSts 3;
BA_ "GenSigStartValue" SG_ 2566799393 ReverseLampSts 3;
BA_ "GenSigStartValue" SG_ 2566799393 CenterStopLampSts 3;
BA_ "GenSigStartValue" SG_ 2566799393 PostionLampSts 3;
VAL_ 2566844672 ParkingBrakeSwitch 3 "NA" 2 "Error" 1 "Parking brake set" 0 "Parking brake not set" ;
VAL_ 2566844672 CruiseCtrlPauseSwitch 3 "NA" 2 "Error" 1 "ON" 0 "OFF" ;
VAL_ 2566844672 CruiseCtrlActive 3 "Not available" 2 " Error" 1 " Cruise control switched on" 0 "Cruise control switched off" ;
VAL_ 2566844672 CruiseCtrlEnableSwitch 3 " NA" 2 " Error" 1 "Cruise control enabled" 0 " Cruise control disabled" ;
VAL_ 2566844672 BrakeSwitch 3 "  Not Available" 2 "  Error" 1 " Brake pedal depressed" 0 "  Brake pedal released" ;
VAL_ 2566844672 ClutchSwitch 3 " Not available" 2 "Error" 1 "Clutch pedal depressed" 0 "Clutch pedal released" ;
VAL_ 2566844672 CruiseCtrlResumeSwitch 3 "NA" 2 "Error" 1 "Cruise control activator in position [resume]" 0 "Cruise control activator not in the position  [resume]" ;
VAL_ 2566844672 PTOGovernorState 31 "Not available" 30 "Reserved" 20 "Reserved" 19 "PTO set speed memory 2" 18 "PTO set speed memory 1" 17 "Preprogrammed set speed 8" 16 "Preprogrammed set speed 7" 15 "Preprogrammed set speed 6" 14 "Preprogrammed set speed 5" 13 "Preprogrammed set speed 4" 12 "Preprogrammed set speed 3" 11 "Preprogrammed set speed 2" 10 "Preprogrammed set speed 1" 9 "Accelerator Override" 8 "Accelerate" 7 "Resume" 6 "Decelerate/Coast" 5 "Set" 4 "Remote Standby" 3 "Standby" 2 "Remote Hold" 1 "Hold" 0 "Off/Disabled" ;
VAL_ 2566844672 CruiseCtrlStates 7 "Not available" 6 " Accelerator" 5 "Set" 4 "Resume" 3 " Decelerate" 2 "Accelerate" 1 " Hold" 0 "Off/Disabled" ;
VAL_ 2566834768 EPB_GuardLampSts 3 "保留" 2 "保留" 1 "点亮" 0 "关闭" ;
VAL_ 2566834768 EPB_AmberWarningLightSts 3 "保留" 2 "保留" 1 "点亮" 0 "关闭" ;
VAL_ 2566834768 EPB_RedStopLightSts 3 "保留" 2 "保留" 1 "点亮" 0 "关闭" ;
VAL_ 2566834768 EPB_FaultIndicatorSts 3 "保留" 2 "保留" 1 "点亮" 0 "关闭" ;
VAL_ 2566863952 ReasonforinhibitionofEPBrelease 15 "not available" 14 "error" 13 "Reserved" 5 "Reserved" 4 "Trailer test active" 3 "insufficient air pressure" 2 "External inhibit reason" 1 "Brake pedal not pressed" 0 "no active inhibit reason" ;
VAL_ 2566863952 ReasonforinhibitionofEPBapply 15 "not available" 14 "error" 13 "Reserved" 5 "Reserved" 3 "External inhibit reason" 2 "High vehicle speed" 1 "Workshop mode active" 0 "Parking brake apply not inhibited" ;
VAL_ 2566863952 AmberWarningLampStatus 3 "Take No Action" 2 "Reserved" 1 "Lamp On" 0 "Lamp Off" ;
VAL_ 2566863952 RedStopLampStatus 3 "Take No Action" 2 "Reserved" 1 "Lamp On" 0 "Lamp Off" ;
VAL_ 2566863952 StateofinhibitionofEPBrelease 255 " Not available" 254 "Error" 253 "Reserved" 3 "Reserved" 2 "Auto and manual release inhibited" 1 "Auto release inhibited" 0 "No release inhibit active" ;
VAL_ 2566863952 StateofEPB 255 " Not available" 254 "Error" 253 "Reserved" 7 "Reserved" 6 "XBR braking active" 5 "Secondary braking active" 3 "Parking brake applying" 2 "Parking brake releasing" 1 "Parking brake applied" 0 "Parking brake not applied" ;
VAL_ 2566863952 WorkingmodeofEPB 255 " Not available" 254 "Error" 253 "Reserved" 8 "Reserved" 7 "Internal error" 6 "Remote mode active" 5 "Roller Test Bench Mode Active" 3 "Automatic mode active" 2 "Backup mode active" 1 "Workshop mode active" 0 "Normal mode active" ;
VAL_ 2566863952 Trailertestactivationstate 3 "not available" 2 "error" 1 "Prking brake in trailer test position" 0 "Prking brake not in trailer test position" ;
VAL_ 2566863952 StateofinhibitionofEPBapply 3 "not available" 2 "error" 1 "parking brake automatic apply inhibited" 0 "parking brake apply not inhibited" ;
VAL_ 2566863952 EPBHCUinparkingstate 3 "not available" 2 "error" 1 "Lever in Position" 0 "Lever not in position" ;
VAL_ 2566863952 EPBHCUinreleasestate 3 "not available" 2 "error" 1 "Lever in Position" 0 "Lever not in position" ;
VAL_ 2566834699 ABS_GuardLampSts 3 "保留" 2 "保留" 1 "点亮" 0 "关闭" ;
VAL_ 2566834699 ABS_AmberWarningLightSts 3 "保留" 2 "保留" 1 "点亮" 0 "关闭" ;
VAL_ 2566834699 ABS_RedStopLightSts 3 "保留" 2 "保留" 1 "点亮" 0 "关闭" ;
VAL_ 2566834699 ABS_FaultIndicatorSts 3 "保留" 2 "保留" 1 "点亮" 0 "关闭" ;
VAL_ 2565865739 ASREngCtrlActive 3 "NA" 2 "Reserved" 1 "ASR engine control active" 0 "ASR engine control passive but installed" ;
VAL_ 2565865739 ASRBrakeCtrlActive 3 "NA" 2 "Reserved" 1 "ASR brake control active" 0 "ASR brake control passive but installed" ;
VAL_ 2565865739 ABSActive 3 "NA" 2 "Reserved" 1 "ABS active" 0 "ABS passive but installed" ;
VAL_ 2565865739 EBSBrakeSwitch 3 "NA" 2 "Error" 1 "Brake pedal is being pressed" 0 "Brake pedal is not being pressed" ;
VAL_ 2565865739 ABSOffroadSwitch 3 "NA" 2 "Error" 1 "ABS off-road switch active" 0 "ABS off-road switch passive" ;
VAL_ 2565865739 ASROffroadSwitch 3 "NA" 2 "Error" 1 "ASR off-road switch active" 0 "ASR off-road switch passive" ;
VAL_ 2565865739 ASRHillHolderSwitch 3 "NA" 2 "Error" 1 "Active" 0 "Passive" ;
VAL_ 2565865739 ABSFullyOperational 3 "NA" 2 "Reserved" 1 "Fully Operational" 0 "Not Fully Operational" ;
VAL_ 2565865739 EBSRedWarningSignal 3 "NA" 2 "Reserved" 1 "On" 0 "Off" ;
VAL_ 2565865739 ABS_EBSAmberWarningSignal 3 "NA" 2 "Reserved" 1 "On" 0 "Off" ;
VAL_ 2565865739 ATC_ASRInfoSignal 3 "NA" 2 "Reserved" 1 "On" 0 "Off" ;
VAL_ 2565865739 TrailerMountedABSWarning 3 "NA" 2 "Reserved" 1 "On" 0 "Off" ;
VAL_ 2566767627 BrakeTempWarning 3 "NA" 2 "Reserved" 1 "Active" 0 "Not Active" ;
VAL_ 2566767627 HaltBrakeMode 7 "NA" 6 "Halt brake not functional" 5 "Reserved" 3 "Reserved" 2 "Active,but not functioning properly(warning)" 1 "Active" 0 "Inactive" ;
VAL_ 2566767627 HillHolderMode 7 "NA" 6 "Hill holder not functional" 5 "Reserved" 3 "Reserved" 2 "Active, but will change to inactive in a short time." 1 "Active" 0 "Inactive" ;
VAL_ 2566767627 FoundationBrakeUse 3 "NA" 2 "Reserved" 1 "In use" 0 "Not in use" ;
VAL_ 2566767627 XBRSystemState 3 "NA" 2 "禁用外部制动" 1 "仅允许最高XBR Priority (0x0)的制动" 0 "允许任何外部制动" ;
VAL_ 2566767627 XBRActiveCtrlMode 15 "Take no action" 14 "Reserved" 4 "Reserved" 3 "执行最大XBR减速制动模式" 2 "执行叠加XBR减速制动" 1 "执行驾驶员制动，不执行外部制动指令" 0 "未执行制动指令(default)" ;
VAL_ 2566767627 EmergencyBrakingActive 3 "NA" 2 "Reserved" 1 "Active" 0 "Inactive" ;
VAL_ 2565868307 StatusOfSteerAxle 15 "NA" 14 "Reserved" 6 "Reserved" 5 "axle steering in specal mode (diagnosis calibration mode)" 4 "axle not active because of an error (adhesion steering)" 3 "axle centered because of an error" 2 "axle centered" 1 "Active" 0 "Not active(adhesion steering)" ;
VAL_ 2565868307 SteerableLiftAxleLoweringInhibit 3 "NA" 2 "Reserved" 1 "lowering inhibited" 0 "lowering allowed" ;
VAL_ 2565868307 SteerType 15 "NA" 14 "Reserved" 2 "Reserved" 1 "Auxiliary steering equipment次要转向" 0 "Main steering system主要转向（决定车的前进方向），本项目默认1" ;
VAL_ 2565868307 TypeOfSteerForces 15 "NA" 14 "Reserved" 4 "Reserved" 3 "自跟踪转向" 2 "全电动转向" 1 "电助力转向" 0 "手动转向设备" ;
VAL_ 2565868307 TypeOfSteerTrans 15 "NA" 14 "Reserved" 4 "Reserved" 3 "混合动力转向传动" 2 "纯电动转向传动" 1 "纯液压转向传动" 0 "纯机械转向传动" ;
VAL_ 2565867787 SteerWheelAngleSensorType 3 "NA" 2 "Reserved" 1 "Absolute measuring principle" 0 "Relative measuring principle" ;
VAL_ 2365473062 RunningLightCmd_1 3 "Don't Care" 2 "Reserved" 1 "Activate" 0 "De-activate" ;
VAL_ 2365473062 LowBeamHeadLightCmd_1 3 "Don't Care" 2 "Reserved" 1 "Activate" 0 "De-activate" ;
VAL_ 2365473062 HighBeamHeadLightCmd_1 3 "Don't Care" 2 "Reserved" 1 "Activate" 0 "De-activate" ;
VAL_ 2365473062 TractorFrontFogLightsCmd_1 3 "Don't Care" 2 "Reserved" 1 "Activate" 0 "De-activate" ;
VAL_ 2365473062 RightTurnSignalLightsCmd_1 3 "Don't Care" 2 "Reserved" 1 "Activate" 0 "De-activate" ;
VAL_ 2365473062 LeftTurnSignalLightsCmd_1 3 "Don't Care" 2 "Reserved" 1 "Activate" 0 "De-activate" ;
VAL_ 2365473062 BackUpLightAndAlarmHornCmd_1 3 "Don't Care" 2 "Reserved" 1 "Activate" 0 "De-activate" ;
VAL_ 2365473062 implement_marker_light_command_1 3 "Don't Care" 2 "Reserved" 1 "Activate" 0 "De-activate" ;
VAL_ 2365473062 RearFogLightCmd_1 3 "Don't Care" 2 "Reserved" 1 "Activate" 0 "De-activate" ;
VAL_ 2365473057 RunningLightCmd 3 "Don't Care" 2 "Reserved" 1 "Activate" 0 "De-activate" ;
VAL_ 2365473057 LowBeamHeadLightCmd 3 "Don't Care" 2 "Reserved" 1 "Activate" 0 "De-activate" ;
VAL_ 2365473057 HighBeamHeadLightCmd 3 "Don't Care" 2 "Reserved" 1 "Activate" 0 "De-activate" ;
VAL_ 2365473057 TractorFrontFogLightsCmd 3 "Don't Care" 2 "Reserved" 1 "Activate" 0 "De-activate" ;
VAL_ 2365473057 RightTurnSignalLightsCmd 3 "Don't Care" 2 "Reserved" 1 "Activate" 0 "De-activate" ;
VAL_ 2365473057 LeftTurnSignalLightsCmd 3 "Don't Care" 2 "Reserved" 1 "Activate" 0 "De-activate" ;
VAL_ 2365473057 BackUpLightAndAlarmHornCmd 3 "Don't Care" 2 "Reserved" 1 "Activate" 0 "De-activate" ;
VAL_ 2365473057 CenterStopLightCmd 3 "Don't Care" 2 "Reserved" 1 "Activate" 0 "De-activate" ;
VAL_ 2365473057 implement_marker_light_command 3 "Don't Care" 2 "Reserved" 1 "Activate" 0 "De-activate" ;
VAL_ 2365473057 RearFogLightCmd 3 "Don't Care" 2 "Reserved" 1 "Activate" 0 "De-activate" ;
VAL_ 2365473057 driver_side_cab_dome_light 3 "NA" 2 "Error" 1 "Pressed" 0 "Not Pressed" ;
VAL_ 2365473057 passenger_side_cab_dome_light 3 "NA" 2 "Error" 1 "Pressed" 0 "Not Pressed" ;
VAL_ 2566759713 LockStatusofDoor1_Driver 3 "not available" 2 "error" 1 "Locked" 0 "Unlocked" ;
VAL_ 2566759713 OpenStatusofDoor1_Driver 3 "not available" 2 "error" 1 "door opened" 0 "door closed" ;
VAL_ 2566759713 LockStatusofDoor2_Passenger 3 "not available" 2 "error" 1 "Locked" 0 "Unlocked" ;
VAL_ 2566759713 OpenStatusofDoor2_Passenger 3 "not available" 2 "error" 1 "door opened" 0 "door closed" ;
VAL_ 2365578991 MotorWorkingMode 3 "转子零位标定（保留）" 2 "转速控制模式" 1 "扭矩控制模式" 0 "自由随动模式" ;
VAL_ 2365578991 MotorRotateDirection 3 "不可用" 2 "反向" 1 "正向" 0 "无旋转方向输出" ;
VAL_ 2365578991 MotorSts 15 "不可用" 14 "保留" 7 "保留" 6 "下电状态" 5 "故障状态" 4 "限制状态" 3 "正常状态" 2 "随动状态" 1 "上电状态" 0 "未激活" ;
VAL_ 2365578991 HighPrecisionActualMotorTrq 15 "不可用" 14 "保留" 8 "保留" 7 "+0.875%" 6 "+0.750%" 5 "+0.625%" 4 "+0.500%" 3 "+0.375%" 2 "+0.250%" 1 "+0.125%" 0 "+0.000%" ;
VAL_ 2365578991 HighPrecisionMaxMotorTrq 15 "不可用" 14 "保留" 8 "保留" 7 "+0.875%" 6 "+0.750%" 5 "+0.625%" 4 "+0.500%" 3 "+0.375%" 2 "+0.250%" 1 "+0.125%" 0 "+0.000%" ;
VAL_ 2365578991 HighVoltOffSts 3 "不可用" 2 "保留" 1 "允许高压下电" 0 "不允许高压下电" ;
VAL_ 2365578991 MotorDischargeSts 3 "主动放电退出" 2 "主动放电完成" 1 "主动放电进行" 0 "主动放电未启动" ;
VAL_ 2365578991 MotorFaliureSts 3 "三级故障" 2 "二级故障" 1 "一级故障" 0 "无故障" ;
VAL_ 2566834707 EPS_GuardLampSts 3 "保留" 2 "保留" 1 "点亮" 0 "关闭" ;
VAL_ 2566834707 EPS_AmberWarningLightSts 3 "保留" 2 "保留" 1 "点亮" 0 "关闭" ;
VAL_ 2566834707 EPS_RedStopLightSts 3 "保留" 2 "保留" 1 "点亮" 0 "关闭" ;
VAL_ 2566834707 EPS_FaultIndicatorSts 3 "保留" 2 "保留" 1 "点亮" 0 "关闭" ;
VAL_ 2566845491 Tire_Status 3 "Not Support" 2 "Error" 1 "Tire leak detected" 0 "OK(No Fault)" ;
VAL_ 2566845491 Extended_Tire_Pressure_Support 3 "Not Support" 2 "Error" 1 "Using Extended Ture Pressure" 0 "Not Using Extended Ture Pressure" ;
VAL_ 2566845491 TirePressureThresholdDetection 7 "Not available" 6 "Error indicator" 5 "Reserved" 4 "Reserved" 3 "Under Pressure" 2 "No warning pressure" 1 "Over pressure" 0 "Reserved" ;
VAL_ 2566897971 TireSensorMatchStatus 3 "Not available" 2 "Reserved" 1 "Not Matched" 0 "Matched" ;
VAL_ 2566897971 TireSensorSelfLearningStatus 7 "Not available" 6 "Reserved" 4 "Reserved" 3 "Learning Failure" 2 "Learning Success" 1 "Start Learning" 0 "Inactive" ;
VAL_ 2566897971 TireSensorElectricalFault 3 "Not available" 2 "Sensor Failure" 1 "Battary Low" 0 "Sensor OK" ;
VAL_ 2566897971 TireTemperatureThresholdDetectio 7 "Not available" 6 "Error indicator" 5 "Reserved" 4 "Reserved" 3 "Under temperature" 2 "No warning temperature" 1 "Over temperature" 0 "Reserved" ;
VAL_ 2566834739 TPMS_GuardLampSts 3 "保留" 2 "保留" 1 "点亮" 0 "关闭" ;
VAL_ 2566834739 TPMS_AmberWarningLightSts 3 "保留" 2 "保留" 1 "点亮" 0 "关闭" ;
VAL_ 2566834739 TPMS_RedStopLightSts 3 "保留" 2 "保留" 1 "点亮" 0 "关闭" ;
VAL_ 2566834739 TPMS_FaultIndicatorSts 3 "保留" 2 "保留" 1 "点亮" 0 "关闭" ;
VAL_ 2364539648 AcceleratorPedal1LowIdleSwitch 3 "Not available" 2 "Error" 1 "Accelerator pedal 1 in low idle condition" 0 "Accelerator pedal 1 not in low idle condition" ;
VAL_ 2364539648 AcceleratorPedalKickdownSwitch 3 "Not available" 2 "Error" 1 "Kickdown active" 0 "Kickdown passive" ;
VAL_ 2348810282 OverrideCtrlMode_ACCE 3 "Speed/torque limit control" 2 "Torque control" 1 "Speed control" 0 "Override disabled" ;
VAL_ 2348810282 ReqSpdCtrlConditions_ACCE 3 "Stability Optimized for driveline engaged and/or in lockup condition 2" 2 "Stability Optimized for driveline engaged and/or in lockup condition 1" 1 "Stability Optimized for driveline disengaged and non-lockup conditions" 0 "Transient Optimized for driveline disengaged and non-lockup conditions" ;
VAL_ 2348810282 OverrideCtrlModePriority_ACCE 3 "Low priority" 2 "Medium priority" 1 "High priority" 0 "Highest priority" ;
VAL_ 2348810282 TSC1TransRate_ACCE 7 "Use standard TSC1 transmission rates of 10 ms to engine" 6 "20 ms transmission rate" 5 "50 ms transmission rate" 4 "100 ms transmission rate" 3 "250 ms transmission rate" 2 "500 ms transmission rate" 1 "750 ms transmission rate" 0 "1000 ms transmission rate" ;
VAL_ 2348810282 TSC1CtrlPurpose_ACCE 31 " Temporary Power Train Control (Original use of TSC1 Command)" 30 "Reserved" 5 "Reserved" 4 "P5 = Engine Protection" 3 "P4 = Road Speed Governor" 2 "P3 = PTO Governor" 1 "P2 = Cruise Control" 0 "P1 = Accelerator Pedal/Operator Selection" ;
VAL_ 2349075360 EBIMode 3 "不可用" 2 "允许EBI" 1 "只允许持续制动" 0 "不允许EBI" ;
VAL_ 2349075360 ExternalBrakeReqPriority 3 "低优先级" 2 "中等优先级" 1 "高优先级" 0 "最高优先级" ;
VAL_ 2349075360 ExternalBrakeReqCtrlMode 3 "不可用" 2 "最大模式" 1 "附加模式" 0 "不控制" ;
VAL_ 2566864170 ExtinhibitionRQforPBrelease 2 "inhibit auto and manual" 1 "inhibit auto release" 0 "no inhibit active" ;
VAL_ 2566864170 ExtinhibitionRQforPBapplication 3 "not available" 2 "error" 1 "automatic apply inhibited" 0 "no inhibit active" ;
VAL_ 2566864170 ExtapplicationRQforEPB 3 "not available" 2 "error" 1 "parking brake application requested" 0 "parking brake application not requested" ;
VAL_ 2566864170 ExtreleaseRQforEPB 3 "not available" 2 "error" 1 "parking brake release requested" 0 "parking brake release not requested" ;
VAL_ 2566864170 AutonomousDriving 3 "not available" 2 "error" 1 "autonomous driving" 0 "manual driving" ;
VAL_ 2566857510 ADUStatus 15 "NA" 14 "Error" 13 "Rserved" 2 "Rserved" 1 "Auto" 0 "Manual" ;
VAL_ 2566857510 BrakeSwtich 3 "NA" 2 "Erorr" 1 "Brake pedal depressed" 0 "Brake pedal released" ;
VAL_ 2566858534 Front_Operator_Wiper_Switch_cmd 15 "NA" 14 "Reserved" 6 "Reserved" 5 "Delayed2" 4 "Delayed1" 3 "high" 2 "medium" 1 "low" 0 "off" ;
VAL_ 2566858534 Front_Operator_Washer_Switch_cmd 7 "NA" 6 "Reserved" 3 "Reserved" 1 "low(ON)" 0 "off" ;
VAL_ 2566858534 ADV_to_BCM 15 "not available" 14 "Reserved" 2 "Reserved" 1 "响应" 0 "不响应" ;
VAL_ 2566858534 DriverDoor1UnlockingRequest 3 "not available" 2 "Locked" 1 "Unlocked" 0 "No Request" ;
VAL_ 2566858534 PassengerDoor2UnlockingRequest 3 "not available" 2 "Locked" 1 "Unlocked" 0 "No Request" ;
VAL_ 2566858534 Back_brake_light_cmd 3 "not available" 2 "error" 1 "制动踏板踩下" 0 "制动踏板未踩下" ;
VAL_ 2566858534 Horn_cmd 3 "not available" 2 "Reserved" 1 "开启前后喇叭" 0 "关闭前后喇叭" ;
VAL_ 2566779431 VCUMode 15 "NA" 14 "Error" 1 "Auto" 0 "Manual" ;
VAL_ 2566779431 ManualBrakeSwitch 3 "NA" 2 "Erorr" 1 "Brake pedal depressed" 0 "Brake pedal released" ;
VAL_ 2566769953 FrontOperatorWiperSwitch 15 "Not available" 14 "Reserved" 7 "Reserved" 6 "Reserved" 5 "Delayed 2" 4 "Delayed 1" 3 "High" 2 "Medium" 1 "Low" 0 "Off" ;
VAL_ 2566769953 FrontOperatorWasherSwitch 7 "Not available" 6 "Reserved" 2 "Reserved" 1 "Low(On)" 0 "Off" ;
VAL_ 2566849057 IGOFFPositionLightAlert 3 "NA" 2 "Reserved" 1 "alert" 0 "Not alert" ;
VAL_ 2566849057 LDWSwitchStatus 3 "NA" 2 "Error" 1 "Pressed" 0 "Not pressed" ;
VAL_ 2566849057 FCWSwitchStatus 3 "NA" 2 "Error" 1 "Pressed" 0 "Not pressed" ;
VAL_ 2566849057 ReverseGearSwitch 3 "NA" 2 "Reserved" 1 "Activate" 0 "De-activate" ;
VAL_ 2566849057 RearWorkLampSwitch 3 "NA" 2 "Reserved" 1 "Activate" 0 "De-activate" ;
VAL_ 2566849057 SleepAreaLightSwitch 3 "NA" 2 "Error" 1 "Pressed" 0 "Not pressed" ;
VAL_ 2566849057 IndoorLightSwitch 3 "NA" 2 "Error" 1 "Pressed" 0 "Not pressed" ;
VAL_ 2566849057 HornSwitch 3 "NA" 2 "Error" 1 "Pressed" 0 "Not pressed" ;
VAL_ 2566849057 HornSelectionSwitch 3 "NA" 2 "Reserved" 1 "air horn to be blared" 0 "electric horn to be blared" ;
VAL_ 2566849057 CabDoorWarningOFFSwitch 3 "NA" 2 "Reserved" 1 "Activate" 0 "De-activate" ;
VAL_ 2566849057 AutoLightControlSwitch 3 "NA" 2 "Reserved" 1 "Activate" 0 "De-activate" ;
VAL_ 2566848801 IGNSts 7 "不可用" 6 "错误" 5 "Reserved" 4 "Reserved" 3 "START" 2 "ON" 1 "ACC" 0 "OFF" ;
VAL_ 2566848801 DriverSeatBeltNotFastenedAlert 3 "Not Available" 2 "Reserved" 1 "Alert" 0 "No Alert" ;
VAL_ 2566848801 PassengerSeatBeltNotFastenedAler 3 "Not Available" 2 "Reserved" 1 "Alert" 0 "No Alert" ;
VAL_ 2566849575 HCUSts 3 "绿灯点亮" 2 "黄灯点亮" 1 "报警" 0 "正常；" ;
VAL_ 2566849575 ReadyToDriveSts 3 "绿灯点亮" 2 "黄灯点亮" 1 "红灯点亮" 0 "未就绪；" ;
VAL_ 2566849575 PermittingCharging 3 "Not available" 2 "Reserved" 1 "Permit" 0 "Not Permit" ;
VAL_ 2566849575 SleepCommand 3 "Not available" 2 "Reserved" 1 "Sleep Command" 0 "No Command" ;
VAL_ 2566849575 HighVoltageSystemFailureStatus 3 "Level 3 Failure" 2 "Level 2 Failure" 1 "Level 1 Failure" 0 "No Error" ;
VAL_ 2566862323 PowerBatterySystemStatus 7 "Reserved" 4 "Reserved" 3 "Third Alarm" 2 "Second Alarm" 1 "First Alarm" 0 "Normal" ;
VAL_ 2566862323 PowerBatteryChargingRequest 7 "Reserved" 4 "Reserved" 3 "Undercharge request (Reserved)" 2 "Charging stop request (Reserved)" 1 "Charge request" 0 "No charge request" ;
VAL_ 2566862323 PowerBatteryChargingStatus 3 "Charge fault" 2 "Charging completed" 1 "Charging" 0 "No charging" ;
VAL_ 2566862323 PowerBatteryheatingStatus 3 "Heating complete" 2 "Heating failure" 1 "Heating" 0 "No heating" ;
VAL_ 2566863603 BMSMainnegativeCoilDriveState 3 "NA" 2 "Reserved" 1 "Connect" 0 "Disconnect" ;
VAL_ 2566863603 MainNegativeRelayDisconnectReque 3 "NA" 2 "Reserved" 1 "Disconnect Request" 0 "No request" ;
VAL_ 2566863603 MainNegativeRelayStatus 7 "NA" 6 "Reserved" 4 "Reserved" 3 "normally open" 2 "adhesion" 1 "Connect" 0 "Disconnect" ;
VAL_ 2566863603 PositiveRelayControlCommand 3 "NA" 2 "Reserved" 1 "Connect" 0 "Disconnect" ;
VAL_ 2566863603 NegativeRelayControlCommand 3 "NA" 2 "Reserved" 1 "Connect" 0 "Disconnect" ;
VAL_ 2566863603 ChargingPlugConnectionStatus 3 "Heating complete" 2 "Heating failure" 1 "Heating" 0 "No heating" ;
VAL_ 2566863603 ChargingPlugConnectionStatus2 3 "Heating complete" 2 "Heating failure" 1 "Heating" 0 "No heating" ;
VAL_ 2566863603 PositiveRelayStatus 7 "NA" 6 "Reserved" 4 "Reserved" 3 "normally open" 2 "adhesion" 1 "Connect" 0 "Disconnect" ;
VAL_ 2566863603 NegativeRelayStatus 7 "NA" 6 "Reserved" 4 "Reserved" 3 "normally open" 2 "adhesion" 1 "Connect" 0 "Disconnect" ;
VAL_ 2566834721 BCM_AmberWarningLightSts 3 "保留" 2 "保留" 1 "点亮" 0 "关闭" ;
VAL_ 2566834721 BCM_RedStopLightSts 3 "保留" 2 "保留" 1 "点亮" 0 "关闭" ;
VAL_ 2348814378 OverrideCtrlMode_ACCDR 3 "Speed/torque limit control" 2 "Torque control" 1 "Speed control" 0 "Override disabled" ;
VAL_ 2348814378 RequestedSpeedControlConditions 3 "Stability Optimized for driveline engaged and/or in lockup condition 2" 2 "Stability Optimized for driveline engaged and/or in lockup condition 1" 1 "Stability Optimized for driveline disengaged and non-lockup conditions" 0 "Transient Optimized for driveline disengaged and non-lockup conditions" ;
VAL_ 2348814378 OverrideCtrlModePriority_ACCDR 3 "Low priority" 2 "Medium priority" 1 "High priority" 0 "Highest priority" ;
VAL_ 2348814378 TSC1TransRate_ACCDR 7 "Use standard TSC1 transmission rates of 10 ms to engine" 6 "20 ms transmission rate" 5 "50 ms transmission rate" 4 "100 ms transmission rate" 3 "250 ms transmission rate" 2 "500 ms transmission rate" 1 "750 ms transmission rate" 0 "1000 ms transmission rate" ;
VAL_ 2348814378 TSC1CtrlPurpose_ACCDR 31 " Temporary Power Train Control (Original use of TSC1 Command)" 30 "Reserved" 5 "Reserved" 4 "P5 = Engine Protection" 3 "P4 = Road Speed Governor" 2 "P3 = PTO Governor" 1 "P2 = Cruise Control" 0 "P1 = Accelerator Pedal/Operator Selection" ;
VAL_ 2348814378 EngReqTorqueHghResolution_ACCDR 15 "NA" 8 "NA" 7 "+0.875%" 6 "+0.750%" 5 "+0.625%" 4 "+0.500%" 3 "+0.375%" 2 "+0.250%" 1 "+0.125%" 0 "+0.000%" ;
VAL_ 2566894099 EPSControllerStatus 15 "不可用" 14 "保留" 8 "保留" 7 "警告模式（有电动助力，无法进入自动驾驶模式）" 6 "警告模式（有电动助力，无法进入自动驾驶模式）" 5 "人工介入模式" 4 "手动模式" 3 "力矩叠加模式" 2 "保留" 1 "自动驾驶模式" 0 "待机模式" ;
VAL_ 2566893862 OperatingModeInstruction 15 "不可用" 14 "保留" 8 "保留" 7 "警告模式（有电动助力，无法进入自动驾驶模式）" 6 "警告模式（有电动助力，无法进入自动驾驶模式）" 5 "人工介入模式" 4 "手动模式" 3 "力矩叠加模式" 2 "保留" 1 "自动驾驶模式" 0 "待机模式" ;
VAL_ 2566893862 ADV_status 1 "ADV状态正常" 0 "ADV状态异常" ;
VAL_ 2566893862 SteeringAngleCommand 1 "正常" 0 "态异常" ;
VAL_ 2566799393 RunningLightSts 3 "不可用" 2 "故障" 1 "点亮" 0 "关闭" ;
VAL_ 2566799393 LowBeamSts 3 "不可用" 2 "故障" 1 "点亮" 0 "关闭" ;
VAL_ 2566799393 HighBeamSts 3 "不可用" 2 "故障" 1 "点亮" 0 "关闭" ;
VAL_ 2566799393 RightLampSts 3 "不可用" 2 "故障" 1 "点亮" 0 "关闭" ;
VAL_ 2566799393 LeftLampSts 3 "不可用" 2 "故障" 1 "点亮" 0 "关闭" ;
VAL_ 2566799393 FrontFogLampSts 3 "不可用" 2 "故障" 1 "点亮" 0 "关闭" ;
VAL_ 2566799393 RearFogLampSts 3 "不可用" 2 "故障" 1 "点亮" 0 "关闭" ;
VAL_ 2566799393 ReverseLampSts 3 "不可用" 2 "故障" 1 "点亮" 0 "关闭" ;
VAL_ 2566799393 CenterStopLampSts 3 "不可用" 2 "故障" 1 "点亮" 0 "关闭" ;
VAL_ 2566799393 PostionLampSts 3 "不可用" 2 "故障" 1 "点亮" 0 "关闭" ;
VAL_ 2566860065 BCMRespSts 15 "无效" 14 "保留" 3 "保留" 2 "故障状态" 1 "响应ADV请求状态" 0 "Stand by状态" ;
VAL_ 2566860065 BrakeLampSts 3 "不可用" 2 "故障" 1 "点亮" 0 "关闭" ;
VAL_ 2566860065 HornContrlSts 3 "不可用" 2 "保留" 1 "开启" 0 "关闭" ;
VAL_ 2566860065 WiperContrlSts 15 "NA" 14 "Reserved" 6 "Reserved" 5 "interval level2" 4 "interval level1" 3 "high" 2 "medium" 1 "low" 0 "off" ;
VAL_ 2566834931 BMS_GuardLampSts 3 "保留" 2 "保留" 1 "点亮" 0 "关闭" ;
VAL_ 2566834931 BMS_AmberWarningLightSts 3 "保留" 2 "保留" 1 "点亮" 0 "关闭" ;
VAL_ 2566834931 BMS_RedStopLightSts 3 "保留" 2 "保留" 1 "点亮" 0 "关闭" ;
VAL_ 2566834931 BMS_FaultIndicatorSts 3 "保留" 2 "保留" 1 "点亮" 0 "关闭" ;
VAL_ 2566834931 BMS_GuardLampBlinking 3 "保留" 2 "闪烁" 1 "点亮" 0 "关闭" ;
VAL_ 2566834931 BMS_AmberWarningLightBlinking 3 "保留" 2 "闪烁" 1 "点亮" 0 "关闭" ;
VAL_ 2566834931 BMS_RedStopLightBlingking 3 "保留" 2 "闪烁" 1 "点亮" 0 "关闭" ;
VAL_ 2566834931 BMS_FaultIndicatorBlinking 3 "保留" 2 "闪烁" 1 "点亮" 0 "关闭" ;
VAL_ 2566834784 PTU_GuardLampSts 3 "保留" 2 "保留" 1 "点亮" 0 "关闭" ;
VAL_ 2566834784 PTU_AmberWarningLightSts 3 "保留" 2 "保留" 1 "点亮" 0 "关闭" ;
VAL_ 2566834784 PTU_RedStopLightSts 3 "保留" 2 "保留" 1 "点亮" 0 "关闭" ;
VAL_ 2566834784 PTU_FaultIndicatorSts 3 "保留" 2 "保留" 1 "点亮" 0 "关闭" ;
VAL_ 2566834784 PTU_GuardLampBlinking 3 "保留" 2 "闪烁" 1 "点亮" 0 "关闭" ;
VAL_ 2566834784 PTU_AmberWarningLightBlinking 3 "保留" 2 "闪烁" 1 "点亮" 0 "关闭" ;
VAL_ 2566834784 PTU_RedStopLightBlingking 3 "保留" 2 "闪烁" 1 "点亮" 0 "关闭" ;
VAL_ 2566834784 PTU_FaultIndicatorBlinking 3 "保留" 2 "闪烁" 1 "点亮" 0 "关闭" ;
VAL_ 2566834741 DCDC2_GuardLampSts 3 "保留" 2 "保留" 1 "点亮" 0 "关闭" ;
VAL_ 2566834741 DCDC2_AmberWarningLightSts 3 "保留" 2 "保留" 1 "点亮" 0 "关闭" ;
VAL_ 2566834741 DCDC2_RedStopLightSts 3 "保留" 2 "保留" 1 "点亮" 0 "关闭" ;
VAL_ 2566834741 DCDC2_FaultIndicatorSts 3 "保留" 2 "保留" 1 "点亮" 0 "关闭" ;
VAL_ 2566834741 DCDC2_GuardLampBlinking 3 "保留" 2 "闪烁" 1 "点亮" 0 "关闭" ;
VAL_ 2566834741 DCDC2_AmberWarningLightBlinking 3 "保留" 2 "闪烁" 1 "点亮" 0 "关闭" ;
VAL_ 2566834741 DCDC2_RedStopLightBlingking 3 "保留" 2 "闪烁" 1 "点亮" 0 "关闭" ;
VAL_ 2566834741 DCDC2_FaultIndicatorBlinking 3 "保留" 2 "闪烁" 1 "点亮" 0 "关闭" ;
VAL_ 2566834736 APCU_GuardLampSts 3 "保留" 2 "保留" 1 "点亮" 0 "关闭" ;
VAL_ 2566834736 APCU_AmberWarningLightSts 3 "保留" 2 "保留" 1 "点亮" 0 "关闭" ;
VAL_ 2566834736 APCU_RedStopLightSts 3 "保留" 2 "保留" 1 "点亮" 0 "关闭" ;
VAL_ 2566834736 APCU_FaultIndicatorSts 3 "保留" 2 "保留" 1 "点亮" 0 "关闭" ;
VAL_ 2566834736 APCU_GuardLampBlinking 3 "保留" 2 "闪烁" 1 "点亮" 0 "关闭" ;
VAL_ 2566834736 APCU_AmberWarningLightBlinking 3 "保留" 2 "闪烁" 1 "点亮" 0 "关闭" ;
VAL_ 2566834736 APCU_RedStopLightBlingking 3 "保留" 2 "闪烁" 1 "点亮" 0 "关闭" ;
VAL_ 2566834736 APCU_FaultIndicatorBlinking 3 "保留" 2 "闪烁" 1 "点亮" 0 "关闭" ;
